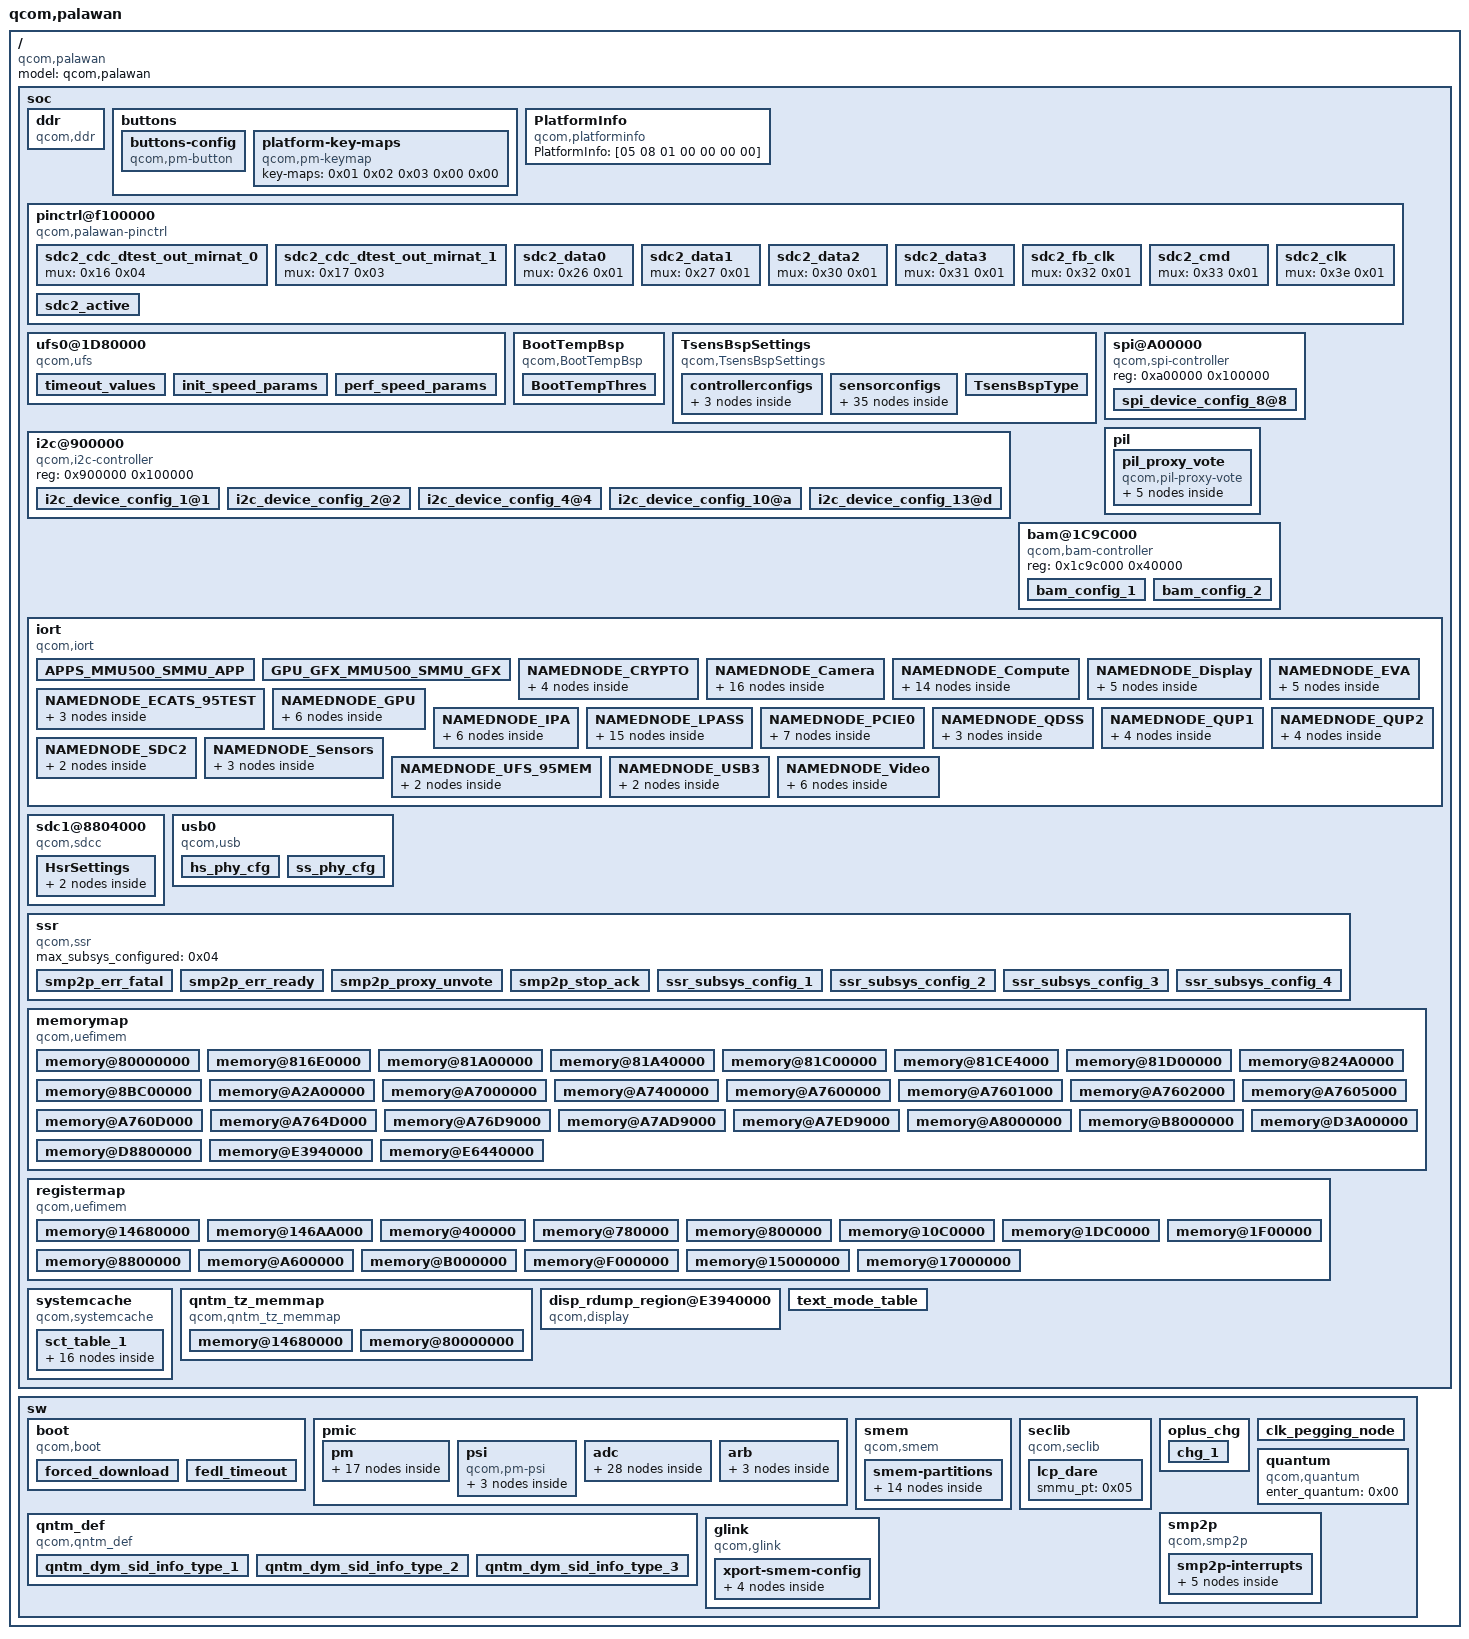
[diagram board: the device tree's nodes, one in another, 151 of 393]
/dts-v1/;

/ {
	compatible = "qcom,palawan";
	model = "qcom,palawan";
	#address-cells = <0x02>;
	#size-cells = <0x02>;

	soc {
		#address-cells = <0x01>;
		#size-cells = <0x01>;
		phandle = <0x10>;

		ddr {
			compatible = "qcom,ddr";
			print_severity = <0x2012>;
			ddr_log_level = <0x00>;
			ddr_trng_always_en = <0x00>;
			extnd_term_log_flag = <0x01>;
			ddr_tr_led_flag = <0x00>;
			ddr_boot_freq = <0x1fef00>;
		};

		buttons {
			phandle = <0x11>;

			buttons-config {
				compatible = "qcom,pm-button";
				gpio-configs = <0x00 0x01 0x01 0x05 0x00 0x01 0x00 0x00>;
			};

			platform-key-maps {
				compatible = "qcom,pm-keymap";
				key-maps = <0x01 0x02 0x03 0x00 0x00>;
			};
		};

		PlatformInfo {
			compatible = "qcom,platforminfo";
			PlatformInfo = [05 08 01 00 00 00 00];
		};

		pinctrl@f100000 {
			compatible = "qcom,palawan-pinctrl";
			reg = <0xf100000 0x100000>;
			ngpios = <0xb2>;
			width = <0x1000>;
			id = <0x00>;
			version = <0x01>;
			gpio-controller;
			#gpio-cells = <0x02>;
			qcom,sleep-config = <0x51 0x51 0x51 0x51 0x45 0x45 0x45 0x45 0x45 0x45 0x45 0x45 0x45 0x45 0x45 0x45 0x18a 0x18a 0x45 0x45 0x45 0x45 0x18a 0x45 0x45 0x45 0x45 0x45 0x45 0x45 0x45 0x151 0x151 0x45 0x45 0x45 0x18a 0x18a 0x45 0x45 0x45 0x45 0x18a 0x45 0x18a 0x18a 0x45 0x45 0x45 0x45 0x45 0x45 0x18a 0x18a 0x45 0x45 0x151 0x18a 0x18a 0x18a 0x45 0x45 0x45 0x45 0x45 0x45 0x45 0x45 0x45 0x45 0x45 0x45 0x45 0x45 0x45 0x45 0x45 0x45 0x45 0x45 0x45 0x18a 0x18a 0x45 0x45 0x45 0x45 0x45 0x152 0x152 0x152 0x45 0x151 0x151 0x151 0x151 0x151 0x151 0x151 0x151 0x45 0x45 0x45 0x45 0x45 0x45 0x45 0x45 0x45 0x45 0x45 0x45 0x45 0x45 0x45 0x45 0x45 0x151 0x18a 0x45 0x45 0x45 0x45 0x45 0x45 0x45 0x45 0x45 0x45 0x45 0x189 0x45 0x151 0x151 0x45 0x151 0x151 0x45 0x45 0x45 0x45 0x45 0x45 0x45 0x45 0x45 0x45 0x45 0x45 0x45 0x45 0x45 0x45 0x45 0x45 0x45 0x45 0x45 0x61 0x61 0x51 0x51 0x61 0x61 0x61 0x61 0x51 0x51 0x45 0x45 0x45 0x45 0x89 0x45 0x45 0x45 0x45 0x45>;
			phandle = <0x12>;

			sdc2_cdc_dtest_out_mirnat_0 {
				mux = <0x16 0x04>;
				phandle = <0x13>;
			};

			sdc2_cdc_dtest_out_mirnat_1 {
				mux = <0x17 0x03>;
				phandle = <0x14>;
			};

			sdc2_data0 {
				mux = <0x26 0x01>;
				phandle = <0x01>;
			};

			sdc2_data1 {
				mux = <0x27 0x01>;
				phandle = <0x02>;
			};

			sdc2_data2 {
				mux = <0x30 0x01>;
				phandle = <0x03>;
			};

			sdc2_data3 {
				mux = <0x31 0x01>;
				phandle = <0x04>;
			};

			sdc2_fb_clk {
				mux = <0x32 0x01>;
				phandle = <0x05>;
			};

			sdc2_cmd {
				mux = <0x33 0x01>;
				phandle = <0x06>;
			};

			sdc2_clk {
				mux = <0x3e 0x01>;
				phandle = <0x07>;
			};

			sdc2_active {
				config = <0x01 0x4b0000a 0x02 0x4b0000a 0x03 0x4b0000a 0x04 0x4b0000a 0x05 0x4b00012 0x06 0x4b00012 0x07 0x4b00012>;
				phandle = <0x0a>;
			};
		};

		ufs0@1D80000 {
			compatible = "qcom,ufs";
			reg = <0x1d80000 0x7000>;
			EnableLogging = [00];
			FUA_Value = [01];
			LinkStartupRetryCount = [05];
			BatteryThresholdMv = <0xe10>;
			phandle = <0x15>;

			timeout_values {
				fDeviceInitTimeoutUs = <0x2625a0>;
				UTRDPollTimeoutUs = <0x1c9c380>;
			};

			init_speed_params {
				EnableHighSpeed = [01];
				NumGears = [05];
				NumLanes = [02];
				Rate = [02];
			};

			perf_speed_params {
				EnableHighSpeed = [01];
				NumGears = [05];
				NumLanes = [02];
				Rate = [02];
			};
		};

		BootTempBsp {
			compatible = "qcom,BootTempBsp";

			BootTempThres {
				nUpperThresholdDegC = <0x96>;
				nLowerThresholdDegC = <0xffffff6a>;
				uMaxNumIterations = <0x28>;
				uWaitPerIterationMicroSec = <0x7a120>;
				uSensor = <0x00>;
			};
		};

		TsensBspSettings {
			compatible = "qcom,TsensBspSettings";

			controllerconfigs {

				controllerconfigs_0 {
					pucTsensSROTPhys = <0x00 0xc222000>;
					pucTsensTMPhys = <0x00 0xc228000>;
					pauTbcbReqs = <0x00 0x00>;
					uTsensSROTSize = <0x1000>;
					uTsensTMSize = <0x1000>;
					uNumTbcbClients = <0x00>;
					uPeriodActive = <0x00>;
					uPeriodSleep = <0x40>;
					uTSControl = <0x20000000>;
					uTSConfig = <0x00>;
					uSidebandEnMask = <0x3fff>;
					uWatchdogLoadVal = <0x267a>;
					uZeroCEnMask = <0x3fff>;
					nsZeroCSetDeciDegC = [00 32];
					nsZeroCResetDeciDegC = [00 64];
					bPSHoldResetEn = [01];
					bAutoAdjustPeriod = [01];
					bStandAlone = [00];
					bPWMEn = [00];
					bWatchdogEn = [01];
					bWatchdogResetEn = [01];
				};

				controllerconfigs_1 {
					pucTsensSROTPhys = <0x00 0xc223000>;
					pucTsensTMPhys = <0x00 0xc229000>;
					pauTbcbReqs = <0x00 0x00>;
					uTsensSROTSize = <0x1000>;
					uTsensTMSize = <0x1000>;
					uNumTbcbClients = <0x00>;
					uPeriodActive = <0x00>;
					uPeriodSleep = <0x40>;
					uTSControl = <0x20000000>;
					uTSConfig = <0x00>;
					uSidebandEnMask = <0xffff>;
					uWatchdogLoadVal = <0x267a>;
					uZeroCEnMask = <0xffff>;
					nsZeroCSetDeciDegC = [00 32];
					nsZeroCResetDeciDegC = [00 64];
					bPSHoldResetEn = [01];
					bAutoAdjustPeriod = [01];
					bStandAlone = [00];
					bPWMEn = [00];
					bWatchdogEn = [01];
					bWatchdogResetEn = [01];
				};

				controllerconfigs_2 {
					pucTsensSROTPhys = <0x00 0xc224000>;
					pucTsensTMPhys = <0x00 0xc22a000>;
					pauTbcbReqs = <0x00 0x00>;
					uTsensSROTSize = <0x1000>;
					uTsensTMSize = <0x1000>;
					uNumTbcbClients = <0x00>;
					uPeriodActive = <0x00>;
					uPeriodSleep = <0x40>;
					uTSControl = <0x20000000>;
					uTSConfig = <0x00>;
					uSidebandEnMask = <0x1f>;
					uWatchdogLoadVal = <0x267a>;
					uZeroCEnMask = <0x1f>;
					nsZeroCSetDeciDegC = [00 32];
					nsZeroCResetDeciDegC = [00 64];
					bPSHoldResetEn = [01];
					bAutoAdjustPeriod = [01];
					bStandAlone = [00];
					bPWMEn = [00];
					bWatchdogEn = [01];
					bWatchdogResetEn = [01];
				};
			};

			sensorconfigs {

				sensorconfigs_0 {
					eCal = <0x00>;
					nsCalPoint1CodeDefault = [01 e0];
					nsCalPoint2CodeDefault = [02 ca];
					nsThresholdMinDeciDegC = [7f ff];
					nsThresholdLowerDeciDegC = [7f ff];
					nsThresholdUpperDeciDegC = [7f ff];
					nsThresholdCriticalDeciDegC = [7f ff];
					nsThresholdMaxDeciDegC = [04 b0];
					controller = [00];
					ucChannel = [00];
					ucSensorID = [00];
					ucFuseIdx = [00];
				};

				sensorconfigs_1 {
					eCal = <0x00>;
					nsCalPoint1CodeDefault = [01 e0];
					nsCalPoint2CodeDefault = [02 ca];
					nsThresholdMinDeciDegC = [7f ff];
					nsThresholdLowerDeciDegC = [7f ff];
					nsThresholdUpperDeciDegC = [7f ff];
					nsThresholdCriticalDeciDegC = [7f ff];
					nsThresholdMaxDeciDegC = [04 b0];
					controller = [00];
					ucChannel = [01];
					ucSensorID = [01];
					ucFuseIdx = [01];
				};

				sensorconfigs_2 {
					eCal = <0x00>;
					nsCalPoint1CodeDefault = [01 e0];
					nsCalPoint2CodeDefault = [02 ca];
					nsThresholdMinDeciDegC = [7f ff];
					nsThresholdLowerDeciDegC = [7f ff];
					nsThresholdUpperDeciDegC = [7f ff];
					nsThresholdCriticalDeciDegC = [7f ff];
					nsThresholdMaxDeciDegC = [04 b0];
					controller = [00];
					ucChannel = [02];
					ucSensorID = [02];
					ucFuseIdx = [02];
				};

				sensorconfigs_3 {
					eCal = <0x00>;
					nsCalPoint1CodeDefault = [01 e0];
					nsCalPoint2CodeDefault = [02 ca];
					nsThresholdMinDeciDegC = [7f ff];
					nsThresholdLowerDeciDegC = [7f ff];
					nsThresholdUpperDeciDegC = [7f ff];
					nsThresholdCriticalDeciDegC = [7f ff];
					nsThresholdMaxDeciDegC = [04 b0];
					controller = [00];
					ucChannel = [03];
					ucSensorID = [03];
					ucFuseIdx = [03];
				};

				sensorconfigs_4 {
					eCal = <0x00>;
					nsCalPoint1CodeDefault = [01 e0];
					nsCalPoint2CodeDefault = [02 ca];
					nsThresholdMinDeciDegC = [7f ff];
					nsThresholdLowerDeciDegC = [7f ff];
					nsThresholdUpperDeciDegC = [7f ff];
					nsThresholdCriticalDeciDegC = [7f ff];
					nsThresholdMaxDeciDegC = [04 b0];
					controller = [00];
					ucChannel = [04];
					ucSensorID = [04];
					ucFuseIdx = [04];
				};

				sensorconfigs_5 {
					eCal = <0x00>;
					nsCalPoint1CodeDefault = [01 e0];
					nsCalPoint2CodeDefault = [02 ca];
					nsThresholdMinDeciDegC = [7f ff];
					nsThresholdLowerDeciDegC = [7f ff];
					nsThresholdUpperDeciDegC = [7f ff];
					nsThresholdCriticalDeciDegC = [7f ff];
					nsThresholdMaxDeciDegC = [04 b0];
					controller = [00];
					ucChannel = [05];
					ucSensorID = [05];
					ucFuseIdx = [05];
				};

				sensorconfigs_6 {
					eCal = <0x00>;
					nsCalPoint1CodeDefault = [01 e0];
					nsCalPoint2CodeDefault = [02 ca];
					nsThresholdMinDeciDegC = [7f ff];
					nsThresholdLowerDeciDegC = [7f ff];
					nsThresholdUpperDeciDegC = [7f ff];
					nsThresholdCriticalDeciDegC = [7f ff];
					nsThresholdMaxDeciDegC = [04 b0];
					controller = [00];
					ucChannel = [06];
					ucSensorID = [06];
					ucFuseIdx = [06];
				};

				sensorconfigs_7 {
					eCal = <0x00>;
					nsCalPoint1CodeDefault = [01 e0];
					nsCalPoint2CodeDefault = [02 ca];
					nsThresholdMinDeciDegC = [7f ff];
					nsThresholdLowerDeciDegC = [7f ff];
					nsThresholdUpperDeciDegC = [7f ff];
					nsThresholdCriticalDeciDegC = [7f ff];
					nsThresholdMaxDeciDegC = [04 b0];
					controller = [00];
					ucChannel = [07];
					ucSensorID = [07];
					ucFuseIdx = [07];
				};

				sensorconfigs_8 {
					eCal = <0x00>;
					nsCalPoint1CodeDefault = [01 e0];
					nsCalPoint2CodeDefault = [02 ca];
					nsThresholdMinDeciDegC = [7f ff];
					nsThresholdLowerDeciDegC = [7f ff];
					nsThresholdUpperDeciDegC = [7f ff];
					nsThresholdCriticalDeciDegC = [7f ff];
					nsThresholdMaxDeciDegC = [04 b0];
					controller = [00];
					ucChannel = [08];
					ucSensorID = [08];
					ucFuseIdx = [08];
				};

				sensorconfigs_9 {
					eCal = <0x00>;
					nsCalPoint1CodeDefault = [01 e0];
					nsCalPoint2CodeDefault = [02 ca];
					nsThresholdMinDeciDegC = [7f ff];
					nsThresholdLowerDeciDegC = [7f ff];
					nsThresholdUpperDeciDegC = [7f ff];
					nsThresholdCriticalDeciDegC = [7f ff];
					nsThresholdMaxDeciDegC = [04 b0];
					controller = [00];
					ucChannel = [09];
					ucSensorID = [09];
					ucFuseIdx = [09];
				};

				sensorconfigs_10 {
					eCal = <0x00>;
					nsCalPoint1CodeDefault = [01 e0];
					nsCalPoint2CodeDefault = [02 ca];
					nsThresholdMinDeciDegC = [7f ff];
					nsThresholdLowerDeciDegC = [7f ff];
					nsThresholdUpperDeciDegC = [7f ff];
					nsThresholdCriticalDeciDegC = [7f ff];
					nsThresholdMaxDeciDegC = [04 b0];
					controller = [00];
					ucChannel = [0a];
					ucSensorID = [0a];
					ucFuseIdx = [0a];
				};

				sensorconfigs_11 {
					eCal = <0x00>;
					nsCalPoint1CodeDefault = [01 e0];
					nsCalPoint2CodeDefault = [02 ca];
					nsThresholdMinDeciDegC = [7f ff];
					nsThresholdLowerDeciDegC = [7f ff];
					nsThresholdUpperDeciDegC = [7f ff];
					nsThresholdCriticalDeciDegC = [7f ff];
					nsThresholdMaxDeciDegC = [04 b0];
					controller = [00];
					ucChannel = [0b];
					ucSensorID = [0b];
					ucFuseIdx = [0b];
				};

				sensorconfigs_12 {
					eCal = <0x00>;
					nsCalPoint1CodeDefault = [01 e0];
					nsCalPoint2CodeDefault = [02 ca];
					nsThresholdMinDeciDegC = [7f ff];
					nsThresholdLowerDeciDegC = [7f ff];
					nsThresholdUpperDeciDegC = [7f ff];
					nsThresholdCriticalDeciDegC = [7f ff];
					nsThresholdMaxDeciDegC = [04 b0];
					controller = [00];
					ucChannel = [0c];
					ucSensorID = [0c];
					ucFuseIdx = [0c];
				};

				sensorconfigs_13 {
					eCal = <0x00>;
					nsCalPoint1CodeDefault = [01 e0];
					nsCalPoint2CodeDefault = [02 ca];
					nsThresholdMinDeciDegC = [7f ff];
					nsThresholdLowerDeciDegC = [7f ff];
					nsThresholdUpperDeciDegC = [7f ff];
					nsThresholdCriticalDeciDegC = [7f ff];
					nsThresholdMaxDeciDegC = [04 b0];
					controller = [00];
					ucChannel = [0d];
					ucSensorID = [0d];
					ucFuseIdx = [0d];
				};

				sensorconfigs_14 {
					eCal = <0x00>;
					nsCalPoint1CodeDefault = [01 e0];
					nsCalPoint2CodeDefault = [02 ca];
					nsThresholdMinDeciDegC = [7f ff];
					nsThresholdLowerDeciDegC = [7f ff];
					nsThresholdUpperDeciDegC = [7f ff];
					nsThresholdCriticalDeciDegC = [7f ff];
					nsThresholdMaxDeciDegC = [04 b0];
					controller = [01];
					ucChannel = [00];
					ucSensorID = [00];
					ucFuseIdx = [0e];
				};

				sensorconfigs_15 {
					eCal = <0x00>;
					nsCalPoint1CodeDefault = [01 e0];
					nsCalPoint2CodeDefault = [02 ca];
					nsThresholdMinDeciDegC = [7f ff];
					nsThresholdLowerDeciDegC = [7f ff];
					nsThresholdUpperDeciDegC = [7f ff];
					nsThresholdCriticalDeciDegC = [7f ff];
					nsThresholdMaxDeciDegC = [04 b0];
					controller = [01];
					ucChannel = [01];
					ucSensorID = [01];
					ucFuseIdx = [0f];
				};

				sensorconfigs_16 {
					eCal = <0x00>;
					nsCalPoint1CodeDefault = [01 e0];
					nsCalPoint2CodeDefault = [02 ca];
					nsThresholdMinDeciDegC = [7f ff];
					nsThresholdLowerDeciDegC = [7f ff];
					nsThresholdUpperDeciDegC = [7f ff];
					nsThresholdCriticalDeciDegC = [7f ff];
					nsThresholdMaxDeciDegC = [04 b0];
					controller = [01];
					ucChannel = [02];
					ucSensorID = [02];
					ucFuseIdx = [10];
				};

				sensorconfigs_17 {
					eCal = <0x00>;
					nsCalPoint1CodeDefault = [01 e0];
					nsCalPoint2CodeDefault = [02 ca];
					nsThresholdMinDeciDegC = [7f ff];
					nsThresholdLowerDeciDegC = [7f ff];
					nsThresholdUpperDeciDegC = [7f ff];
					nsThresholdCriticalDeciDegC = [7f ff];
					nsThresholdMaxDeciDegC = [04 b0];
					controller = [01];
					ucChannel = [03];
					ucSensorID = [03];
					ucFuseIdx = [11];
				};

				sensorconfigs_18 {
					eCal = <0x00>;
					nsCalPoint1CodeDefault = [01 e0];
					nsCalPoint2CodeDefault = [02 ca];
					nsThresholdMinDeciDegC = [7f ff];
					nsThresholdLowerDeciDegC = [7f ff];
					nsThresholdUpperDeciDegC = [7f ff];
					nsThresholdCriticalDeciDegC = [7f ff];
					nsThresholdMaxDeciDegC = [04 b0];
					controller = [01];
					ucChannel = [04];
					ucSensorID = [04];
					ucFuseIdx = [12];
				};

				sensorconfigs_19 {
					eCal = <0x00>;
					nsCalPoint1CodeDefault = [01 e0];
					nsCalPoint2CodeDefault = [02 ca];
					nsThresholdMinDeciDegC = [7f ff];
					nsThresholdLowerDeciDegC = [7f ff];
					nsThresholdUpperDeciDegC = [7f ff];
					nsThresholdCriticalDeciDegC = [7f ff];
					nsThresholdMaxDeciDegC = [04 b0];
					controller = [01];
					ucChannel = [05];
					ucSensorID = [05];
					ucFuseIdx = [13];
				};

				sensorconfigs_20 {
					eCal = <0x00>;
					nsCalPoint1CodeDefault = [01 e0];
					nsCalPoint2CodeDefault = [02 ca];
					nsThresholdMinDeciDegC = [7f ff];
					nsThresholdLowerDeciDegC = [7f ff];
					nsThresholdUpperDeciDegC = [7f ff];
					nsThresholdCriticalDeciDegC = [7f ff];
					nsThresholdMaxDeciDegC = [04 b0];
					controller = [01];
					ucChannel = [06];
					ucSensorID = [06];
					ucFuseIdx = [14];
				};

				sensorconfigs_21 {
					eCal = <0x00>;
					nsCalPoint1CodeDefault = [01 e0];
					nsCalPoint2CodeDefault = [02 ca];
					nsThresholdMinDeciDegC = [7f ff];
					nsThresholdLowerDeciDegC = [7f ff];
					nsThresholdUpperDeciDegC = [7f ff];
					nsThresholdCriticalDeciDegC = [7f ff];
					nsThresholdMaxDeciDegC = [04 b0];
					controller = [01];
					ucChannel = [07];
					ucSensorID = [07];
					ucFuseIdx = [15];
				};

				sensorconfigs_22 {
					eCal = <0x00>;
					nsCalPoint1CodeDefault = [01 e0];
					nsCalPoint2CodeDefault = [02 ca];
					nsThresholdMinDeciDegC = [7f ff];
					nsThresholdLowerDeciDegC = [7f ff];
					nsThresholdUpperDeciDegC = [7f ff];
					nsThresholdCriticalDeciDegC = [7f ff];
					nsThresholdMaxDeciDegC = [04 b0];
					controller = [01];
					ucChannel = [08];
					ucSensorID = [08];
					ucFuseIdx = [16];
				};

				sensorconfigs_23 {
					eCal = <0x00>;
					nsCalPoint1CodeDefault = [01 e0];
					nsCalPoint2CodeDefault = [02 ca];
					nsThresholdMinDeciDegC = [7f ff];
					nsThresholdLowerDeciDegC = [7f ff];
					nsThresholdUpperDeciDegC = [7f ff];
					nsThresholdCriticalDeciDegC = [7f ff];
					nsThresholdMaxDeciDegC = [04 b0];
					controller = [01];
					ucChannel = [09];
					ucSensorID = [09];
					ucFuseIdx = [17];
				};

				sensorconfigs_24 {
					eCal = <0x00>;
					nsCalPoint1CodeDefault = [01 e0];
					nsCalPoint2CodeDefault = [02 ca];
					nsThresholdMinDeciDegC = [7f ff];
					nsThresholdLowerDeciDegC = [7f ff];
					nsThresholdUpperDeciDegC = [7f ff];
					nsThresholdCriticalDeciDegC = [7f ff];
					nsThresholdMaxDeciDegC = [04 b0];
					controller = [01];
					ucChannel = [0a];
					ucSensorID = [0a];
					ucFuseIdx = [18];
				};

				sensorconfigs_25 {
					eCal = <0x00>;
					nsCalPoint1CodeDefault = [01 e0];
					nsCalPoint2CodeDefault = [02 ca];
					nsThresholdMinDeciDegC = [7f ff];
					nsThresholdLowerDeciDegC = [7f ff];
					nsThresholdUpperDeciDegC = [7f ff];
					nsThresholdCriticalDeciDegC = [7f ff];
					nsThresholdMaxDeciDegC = [04 b0];
					controller = [01];
					ucChannel = [0b];
					ucSensorID = [0b];
					ucFuseIdx = [19];
				};

				sensorconfigs_26 {
					eCal = <0x00>;
					nsCalPoint1CodeDefault = [01 e0];
					nsCalPoint2CodeDefault = [02 ca];
					nsThresholdMinDeciDegC = [7f ff];
					nsThresholdLowerDeciDegC = [7f ff];
					nsThresholdUpperDeciDegC = [7f ff];
					nsThresholdCriticalDeciDegC = [7f ff];
					nsThresholdMaxDeciDegC = [04 b0];
					controller = [01];
					ucChannel = [0c];
					ucSensorID = [0c];
					ucFuseIdx = [1a];
				};

				sensorconfigs_27 {
					eCal = <0x00>;
					nsCalPoint1CodeDefault = [01 e0];
					nsCalPoint2CodeDefault = [02 ca];
					nsThresholdMinDeciDegC = [7f ff];
					nsThresholdLowerDeciDegC = [7f ff];
					nsThresholdUpperDeciDegC = [7f ff];
					nsThresholdCriticalDeciDegC = [7f ff];
					nsThresholdMaxDeciDegC = [04 b0];
					controller = [01];
					ucChannel = [0d];
					ucSensorID = [0d];
					ucFuseIdx = [1b];
				};

				sensorconfigs_28 {
					eCal = <0x00>;
					nsCalPoint1CodeDefault = [01 e0];
					nsCalPoint2CodeDefault = [02 ca];
					nsThresholdMinDeciDegC = [7f ff];
					nsThresholdLowerDeciDegC = [7f ff];
					nsThresholdUpperDeciDegC = [7f ff];
					nsThresholdCriticalDeciDegC = [7f ff];
					nsThresholdMaxDeciDegC = [04 b0];
					controller = [01];
					ucChannel = [0e];
					ucSensorID = [0e];
					ucFuseIdx = [1c];
				};

				sensorconfigs_29 {
					eCal = <0x00>;
					nsCalPoint1CodeDefault = [01 e0];
					nsCalPoint2CodeDefault = [02 ca];
					nsThresholdMinDeciDegC = [7f ff];
					nsThresholdLowerDeciDegC = [7f ff];
					nsThresholdUpperDeciDegC = [7f ff];
					nsThresholdCriticalDeciDegC = [7f ff];
					nsThresholdMaxDeciDegC = [04 b0];
					controller = [01];
					ucChannel = [0f];
					ucSensorID = [0f];
					ucFuseIdx = [1d];
				};

				sensorconfigs_30 {
					eCal = <0x00>;
					nsCalPoint1CodeDefault = [01 e0];
					nsCalPoint2CodeDefault = [02 ca];
					nsThresholdMinDeciDegC = [7f ff];
					nsThresholdLowerDeciDegC = [7f ff];
					nsThresholdUpperDeciDegC = [7f ff];
					nsThresholdCriticalDeciDegC = [7f ff];
					nsThresholdMaxDeciDegC = [04 b0];
					controller = [02];
					ucChannel = [00];
					ucSensorID = [00];
					ucFuseIdx = [1e];
				};

				sensorconfigs_31 {
					eCal = <0x00>;
					nsCalPoint1CodeDefault = [01 e0];
					nsCalPoint2CodeDefault = [02 ca];
					nsThresholdMinDeciDegC = [7f ff];
					nsThresholdLowerDeciDegC = [7f ff];
					nsThresholdUpperDeciDegC = [7f ff];
					nsThresholdCriticalDeciDegC = [7f ff];
					nsThresholdMaxDeciDegC = [04 b0];
					controller = [02];
					ucChannel = [01];
					ucSensorID = [01];
					ucFuseIdx = [1f];
				};

				sensorconfigs_32 {
					eCal = <0x00>;
					nsCalPoint1CodeDefault = [01 e0];
					nsCalPoint2CodeDefault = [02 ca];
					nsThresholdMinDeciDegC = [7f ff];
					nsThresholdLowerDeciDegC = [7f ff];
					nsThresholdUpperDeciDegC = [7f ff];
					nsThresholdCriticalDeciDegC = [7f ff];
					nsThresholdMaxDeciDegC = [04 b0];
					controller = [02];
					ucChannel = [02];
					ucSensorID = [02];
					ucFuseIdx = [20];
				};

				sensorconfigs_33 {
					eCal = <0x00>;
					nsCalPoint1CodeDefault = [01 e0];
					nsCalPoint2CodeDefault = [02 ca];
					nsThresholdMinDeciDegC = [7f ff];
					nsThresholdLowerDeciDegC = [7f ff];
					nsThresholdUpperDeciDegC = [7f ff];
					nsThresholdCriticalDeciDegC = [7f ff];
					nsThresholdMaxDeciDegC = [04 b0];
					controller = [02];
					ucChannel = [03];
					ucSensorID = [03];
					ucFuseIdx = [21];
				};

				sensorconfigs_34 {
					eCal = <0x00>;
					nsCalPoint1CodeDefault = [01 e0];
					nsCalPoint2CodeDefault = [02 ca];
					nsThresholdMinDeciDegC = [7f ff];
					nsThresholdLowerDeciDegC = [7f ff];
					nsThresholdUpperDeciDegC = [7f ff];
					nsThresholdCriticalDeciDegC = [7f ff];
					nsThresholdMaxDeciDegC = [04 b0];
					controller = [02];
					ucChannel = [04];
					ucSensorID = [04];
					ucFuseIdx = [22];
				};
			};

			TsensBspType {
				uNumControllers = <0x03>;
				uNumSensors = <0x23>;
				uSensorConvTime_us = <0x1e>;
				nCalPoint1DeciDegC = <0x12c>;
				nCalPoint2DeciDegC = <0x4b0>;
				uShift = <0x0a>;
			};
		};

		i2c@900000 {
			#address-cells = <0x01>;
			#size-cells = <0x00>;
			compatible = "qcom,i2c-controller";
			reg = <0x900000 0x100000>;

			i2c_device_config_1@1 {
				reg = <0x01>;
				status = "okay";
				core_base_addr = <0xa00000>;
				common_base_addr = <0xac0000>;
				core_offset = <0x80000>;
				qupv3_instance = [00];
				core_index = [01];
				se_index = [00];
				gpi_index = [00];
				core_irq = [00];
				polled_mode = [01];
				i2c_hub = [00];
				min_data_length_for_dma = [00];
				scl_encoding = <0x40018351>;
				sda_encoding = <0x40018341>;
				tcsr_reg_offset = <0x00>;
				tcsr_base_addr = <0x1fc0000>;
				tcsr_reg_value = <0x00>;
				se_clock = "gcc_qupv3_wrap0_s0_clk";
			};

			i2c_device_config_2@2 {
				reg = <0x02>;
				status = "okay";
				core_base_addr = <0xa00000>;
				common_base_addr = <0xac0000>;
				core_offset = "", "\b@";
				qupv3_instance = [00];
				core_index = [02];
				se_index = [01];
				gpi_index = [00];
				core_irq = [00];
				polled_mode = [01];
				i2c_hub = [00];
				min_data_length_for_dma = [00];
				scl_encoding = <0x18051>;
				sda_encoding = <0x18041>;
				tcsr_reg_offset = <0x00>;
				tcsr_base_addr = <0x1fc0000>;
				tcsr_reg_value = <0x00>;
				se_clock = "gcc_qupv3_wrap0_s1_clk";
			};

			i2c_device_config_4@4 {
				reg = <0x04>;
				status = "okay";
				core_base_addr = <0xa00000>;
				common_base_addr = <0xac0000>;
				core_offset = <0x8c000>;
				qupv3_instance = [00];
				core_index = [04];
				se_index = [03];
				gpi_index = [03];
				core_irq = [00];
				polled_mode = [01];
				i2c_hub = [00];
				min_data_length_for_dma = [00];
				scl_encoding = <0x400180d2>;
				sda_encoding = <0x400180c2>;
				tcsr_reg_offset = <0x00>;
				tcsr_base_addr = <0x1fc0000>;
				tcsr_reg_value = <0x00>;
				se_clock = "gcc_qupv3_wrap0_s3_clk";
			};

			i2c_device_config_10@a {
				reg = <0x0a>;
				status = "okay";
				core_base_addr = <0x800000>;
				common_base_addr = <0x8c0000>;
				core_offset = "", "\b@";
				qupv3_instance = [01];
				core_index = [0a];
				se_index = [01];
				gpi_index = [09];
				core_irq = [00];
				polled_mode = [01];
				i2c_hub = [00];
				min_data_length_for_dma = [00];
				scl_encoding = <0x18251>;
				sda_encoding = <0x18241>;
				tcsr_reg_offset = <0x00>;
				tcsr_base_addr = <0x1fc0000>;
				tcsr_reg_value = <0x00>;
				se_clock = "gcc_qupv3_wrap1_s1_clk";
			};

			i2c_device_config_13@d {
				reg = <0x0d>;
				status = "okay";
				core_base_addr = <0x800000>;
				common_base_addr = <0x8c0000>;
				core_offset = <0x90000>;
				qupv3_instance = [01];
				core_index = [0d];
				se_index = [04];
				gpi_index = [0c];
				core_irq = [00];
				polled_mode = [01];
				i2c_hub = [00];
				min_data_length_for_dma = [00];
				scl_encoding = <0x18b11>;
				sda_encoding = <0x18b01>;
				tcsr_reg_offset = <0x00>;
				tcsr_base_addr = <0x1fc0000>;
				tcsr_reg_value = <0x00>;
				se_clock = "gcc_qupv3_wrap1_s4_clk";
			};
		};

		spi@A00000 {
			#address-cells = <0x01>;
			#size-cells = <0x00>;
			compatible = "qcom,spi-controller";
			reg = <0xa00000 0x100000>;

			spi_device_config_8@8 {
				reg = <0x08>;
				status = "okay";
				core_base_addr = <0xa00000>;
				common_base_addr = <0xac0000>;
				core_offset = <0x9c000>;
				qupv3_instance = [00];
				core_index = [07];
				se_index = [07];
				gpi_index = [07];
				core_irq = [00];
				polled_mode = [01];
				min_data_length_for_dma = [00];
				qupv3_protocol = [01];
				miso_encoding = <0x481c1>;
				mosi_encoding = <0x4c1d1>;
				clk_encoding = <0x441e1>;
				cs_encoding = <0x4c1f1>;
				sleep_miso_encoding = <0x00>;
				sleep_mosi_encoding = <0x00>;
				sleep_clk_encoding = <0x00>;
				sleep_cs_encoding = <0x00>;
				tcsr_reg_offset = <0x00>;
				tcsr_base_addr = <0x1fc0000>;
				tcsr_reg_value = <0x00>;
				se_clock_frequency = <0x4b00>;
				se_clock_dfs_index = [01];
				se_clock = "gcc_qupv3_wrap0_s7_clk";
			};
		};

		pil {

			pil_proxy_vote {
				compatible = "qcom,pil-proxy-vote";
				phandle = <0x16>;

				pil_proxy_vote_1 {
					subsys_id = <0x01>;
					client_name = "PIL_ADSP";
					rail_names = "/vcs/vdd_lpi_mx", "/vcs/vdd_lpi_cx";
					rail_voltage_levels = <0x100 0x100>;
					icb_name = "/icb/arbiter";
					icb_arb_master_slave = <0x19 0x00>;
					icb_arb_request_type = <0x04>;
					icb_arb_request_data = <0x00 0x5f5e100 0x00 0x5f5e100>;
					flag = <0x03 0x03>;
				};

				pil_proxy_vote_4 {
					subsys_id = <0x04>;
					client_name = "PIL_MODEM";
					rail_names = "/vcs/vdd_mx", "/vcs/vdd_cx", "/vcs/vdd_mxc";
					rail_voltage_levels = <0x100 0x100 0x100>;
					flag = <0x03 0x03>;
				};

				pil_proxy_vote_18 {
					subsys_id = <0x12>;
					client_name = "PIL_CDSP";
					rail_names = "/vcs/vdd_mx", "/vcs/vdd_cx", "/vcs/vdd_mxc", "/vcs/vdd_nsp";
					rail_voltage_levels = <0x100 0x100 0x100 0x100>;
					icb_name = "/icb/arbiter";
					icb_arb_master_slave = <0xad 0x2f>;
					icb_arb_request_type = <0x04>;
					icb_arb_request_data = <0x00 0x5f5e100 0x00 0x5f5e100>;
					flag = <0x02 0x01>;
				};

				pil_proxy_vote_37 {
					subsys_id = <0x25>;
					client_name = "PIL_CDSP";
					rail_names = "/vcs/vdd_mx", "/vcs/vdd_cx", "/vcs/vdd_mxc", "/vcs/vdd_nsp";
					rail_voltage_levels = <0x100 0x100 0x100 0x100>;
					icb_name = "/icb/arbiter";
					icb_arb_master_slave = <0xad 0x2f>;
					icb_arb_request_type = <0x04>;
					icb_arb_request_data = <0x00 0x5f5e100 0x00 0x5f5e100>;
					flag = <0x11 0x12>;
				};

				pil_proxy_vote_6 {
					subsys_id = <0x06>;
					client_name = "PIL_WPSS";
					rail_names = "/vcs/vdd_mx", "/vcs/vdd_cx";
					rail_voltage_levels = <0x100 0x100>;
					flag = <0x03 0x03>;
				};
			};
		};

		bam@1C9C000 {
			compatible = "qcom,bam-controller";
			reg = <0x1c9c000 0x40000>;

			bam_config_1 {
				bam_pa = <0x00 0x1dc4000>;
				options = <0x100>;
				cfg_bits = <0xfffff004>;
				ee = [00];
				sec_config = <0x00 0x00>;
				size = <0x40000>;
			};

			bam_config_2 {
				bam_pa = <0x00 0x00>;
				options = <0x00>;
				cfg_bits = <0x00>;
				ee = [00];
				sec_config = <0x00 0x00>;
				size = <0x00>;
			};
		};

		iort {
			compatible = "qcom,iort";
			Signature = <0x54524f49>;
			Revision = <0x01>;
			Checksum = <0x00>;
			OEMID = "QCOM";
			OEMTableID = <0x51434f4d 0x45444b32>;
			OEMRevision = <0x8998>;
			CreatorID = <0x51434f4d>;
			CreatorRevision = <0x01>;
			NumberofIORTNodes = <0x14>;
			Reserved = <0x00>;
			instance_handles = <0x08 0x09>;

			APPS_MMU500_SMMU_APP {
				Type = <0x03>;
				Revision = <0x01>;
				Reserved = <0x00>;
				NumberofMappings = <0x00>;
				BaseAddress = <0x15000000>;
				Span = <0x80000>;
				Flags = <0x03>;
				Model = <0x03>;
				NumContextInterrupts = <0x60>;
				NumPMUInterrupts = <0x00>;
				NSGIRPT_GSIV = <0x61>;
				NSGIRPT_FLAGS = <0x00>;
				NSGCFGIRPT_GSIV = <0x00>;
				NSGCFGIRPT_FLAGS = <0x00>;
				ContextInterrupts = <0x81 0x82 0x83 0x84 0x85 0x86 0x87 0x88 0x89 0x8a 0x8b 0x8c 0x8d 0x8e 0x8f 0x90 0x91 0x92 0x93 0x94 0x95 0x96 0xd5 0xd6 0xd7 0xd8 0xd9 0xda 0xdb 0xdc 0xdd 0xde 0xdf 0xe0 0x15b 0x15c 0x15d 0x15e 0x15f 0x160 0x161 0x162 0x163 0x164 0x165 0x166 0x167 0x168 0x169 0x16a 0x16b 0x16c 0x16d 0x16e 0x16f 0x170 0x171 0x172 0x173 0x174 0x175 0x176 0x177 0x178 0x179 0x1ab 0x1ac 0x1ad 0x1ae 0x1af 0x1b0 0x1b1 0x1b2 0x1b3 0x1b4 0x1b5 0x1b6 0x1b7 0x1b8 0x1b9 0x1c2 0x1c3 0x1bc 0x1c5 0x2e2 0x1c7 0x1c8 0x1c9 0x2d1 0x2d2 0x2d3 0x2d4 0x2d5 0x2d6 0x2d7 0x2d8>;
				ContextInterruptFlags = <0x00 0x00 0x00 0x00 0x00 0x00 0x00 0x00 0x00 0x00 0x00 0x00 0x00 0x00 0x00 0x00 0x00 0x00 0x00 0x00 0x00 0x00 0x00 0x00 0x00 0x00 0x00 0x00 0x00 0x00 0x00 0x00 0x00 0x00 0x00 0x00 0x00 0x00 0x00 0x00 0x00 0x00 0x00 0x00 0x00 0x00 0x00 0x00 0x00 0x00 0x00 0x00 0x00 0x00 0x00 0x00 0x00 0x00 0x00 0x00 0x00 0x00 0x00 0x00 0x00 0x00 0x00 0x00 0x00 0x00 0x00 0x00 0x00 0x00 0x00 0x00 0x00 0x00 0x00 0x00 0x00 0x00 0x00 0x00 0x00 0x00 0x00 0x00 0x00 0x00 0x00 0x00 0x00 0x00 0x00 0x00>;
				PMUInterrupts = <0x00>;
				PMUInterruptFlags = <0x00>;
				SIDMAPPING = <0x00>;
				phandle = <0x08>;
			};

			GPU_GFX_MMU500_SMMU_GFX {
				Type = <0x03>;
				Revision = <0x01>;
				Reserved = <0x00>;
				NumberofMappings = <0x00>;
				BaseAddress = <0x3da0000>;
				Span = <0x20000>;
				Flags = <0x03>;
				Model = <0x03>;
				NumContextInterrupts = <0x19>;
				NumPMUInterrupts = <0x00>;
				NSGIRPT_GSIV = <0x2c1>;
				NSGIRPT_FLAGS = <0x00>;
				NSGCFGIRPT_GSIV = <0x00>;
				NSGCFGIRPT_FLAGS = <0x00>;
				ContextInterrupts = <0x2c5 0x2c6 0x2c7 0x2c8 0x2c9 0x2ca 0x2cb 0x2cc 0x2cd 0x2ce 0x2cf 0x1c6 0x1fc 0x25e 0x25f 0x260 0x261 0x2b3 0x2b5 0x2b8 0x2b9 0x2ba 0x2bc 0x2bd 0x2db>;
				ContextInterruptFlags = <0x00 0x00 0x00 0x00 0x00 0x00 0x00 0x00 0x00 0x00 0x00 0x00 0x00 0x00 0x00 0x00 0x00 0x00 0x00 0x00 0x00 0x00 0x00 0x00 0x00>;
				PMUInterrupts = <0x00>;
				PMUInterruptFlags = <0x00>;
				SIDMAPPING = <0x00>;
				phandle = <0x09>;
			};

			NAMEDNODE_CRYPTO {
				Type = <0x01>;
				Revision = <0x01>;
				Reserved = <0x00>;
				NumberofMappings = <0x03>;
				NodeFlags = <0x00>;
				CacheCoherency = <0x00>;
				AllocationHints = <0x00>;
				Reserved1 = <0x00>;
				MemAccessFlags = <0x00>;
				DeviceMemAddressSize = <0x24>;
				DevObjectName = "CRYPTO";

				SIDMappings {

					SIDMappings_1 {
						InputBase = <0x3000001>;
						NumIDs = <0x01>;
						OutputBase = <0x481>;
						Flags = <0x00>;
						OutputReference = <0x08>;
					};

					SIDMappings_2 {
						InputBase = <0x3000002>;
						NumIDs = <0x01>;
						OutputBase = <0x480>;
						Flags = <0x00>;
						OutputReference = <0x08>;
					};

					SIDMappings_3 {
						InputBase = <0x3000003>;
						NumIDs = <0x01>;
						OutputBase = <0x483>;
						Flags = <0x00>;
						OutputReference = <0x08>;
					};
				};
			};

			NAMEDNODE_Camera {
				Type = <0x01>;
				Revision = <0x01>;
				Reserved = <0x00>;
				NumberofMappings = <0x0f>;
				NodeFlags = <0x00>;
				CacheCoherency = <0x00>;
				AllocationHints = <0x00>;
				Reserved1 = <0x00>;
				MemAccessFlags = <0x00>;
				DeviceMemAddressSize = <0x24>;
				DevObjectName = "CAMERA";

				SIDMappings {

					SIDMappings_0 {
						InputBase = <0x3000000>;
						NumIDs = <0x01>;
						OutputBase = "", " \b";
						Flags = <0x00>;
						OutputReference = <0x08>;
					};

					SIDMappings_1 {
						InputBase = <0x3000001>;
						NumIDs = <0x01>;
						OutputBase = <0x10200808>;
						Flags = <0x00>;
						OutputReference = <0x08>;
					};

					SIDMappings_3 {
						InputBase = <0x3000003>;
						NumIDs = <0x01>;
						OutputBase = <0x1820>;
						Flags = <0x00>;
						OutputReference = <0x08>;
					};

					SIDMappings_5 {
						InputBase = <0x3000005>;
						NumIDs = <0x01>;
						OutputBase = <0x18c0>;
						Flags = <0x00>;
						OutputReference = <0x08>;
					};

					SIDMappings_6 {
						InputBase = <0x3000006>;
						NumIDs = <0x01>;
						OutputBase = <0x18c2>;
						Flags = <0x00>;
						OutputReference = <0x08>;
					};

					SIDMappings_7 {
						InputBase = <0x3000007>;
						NumIDs = <0x01>;
						OutputBase = <0x1800>;
						Flags = <0x00>;
						OutputReference = <0x08>;
					};

					SIDMappings_8 {
						InputBase = <0x3000008>;
						NumIDs = <0x01>;
						OutputBase = <0x18a0>;
						Flags = <0x00>;
						OutputReference = <0x08>;
					};

					SIDMappings_9 {
						InputBase = <0x3000009>;
						NumIDs = <0x01>;
						OutputBase = <0x1860>;
						Flags = <0x00>;
						OutputReference = <0x08>;
					};

					SIDMappings_10 {
						InputBase = <0x300000a>;
						NumIDs = <0x01>;
						OutputBase = <0x1861>;
						Flags = <0x00>;
						OutputReference = <0x08>;
					};

					SIDMappings_11 {
						InputBase = <0x300000b>;
						NumIDs = <0x01>;
						OutputBase = <0x1840>;
						Flags = <0x00>;
						OutputReference = <0x08>;
					};

					SIDMappings_12 {
						InputBase = <0x300000c>;
						NumIDs = <0x01>;
						OutputBase = <0x1841>;
						Flags = <0x00>;
						OutputReference = <0x08>;
					};

					SIDMappings_13 {
						InputBase = <0x300000d>;
						NumIDs = <0x01>;
						OutputBase = <0x1880>;
						Flags = <0x00>;
						OutputReference = <0x08>;
					};

					SIDMappings_14 {
						InputBase = <0x300000e>;
						NumIDs = <0x01>;
						OutputBase = <0x1881>;
						Flags = <0x00>;
						OutputReference = <0x08>;
					};

					SIDMappings_15 {
						InputBase = <0x300000f>;
						NumIDs = <0x01>;
						OutputBase = <0x18e0>;
						Flags = <0x00>;
						OutputReference = <0x08>;
					};

					SIDMappings_16 {
						InputBase = <0x3000010>;
						NumIDs = <0x01>;
						OutputBase = <0x18e8>;
						Flags = <0x00>;
						OutputReference = <0x08>;
					};
				};
			};

			NAMEDNODE_Compute {
				Type = <0x01>;
				Revision = <0x01>;
				Reserved = <0x00>;
				NumberofMappings = <0x0d>;
				NodeFlags = <0x00>;
				CacheCoherency = <0x00>;
				AllocationHints = <0x00>;
				Reserved1 = <0x00>;
				MemAccessFlags = <0x00>;
				DeviceMemAddressSize = <0x24>;
				DevObjectName = "COMPUTE";

				SIDMappings {

					SIDMappings_1 {
						InputBase = <0x3000001>;
						NumIDs = <0x01>;
						OutputBase = <0xc01>;
						Flags = <0x00>;
						OutputReference = <0x08>;
					};

					SIDMappings_2 {
						InputBase = <0x3000002>;
						NumIDs = <0x01>;
						OutputBase = <0xc02>;
						Flags = <0x00>;
						OutputReference = <0x08>;
					};

					SIDMappings_3 {
						InputBase = <0x3000003>;
						NumIDs = <0x01>;
						OutputBase = <0xc03>;
						Flags = <0x00>;
						OutputReference = <0x08>;
					};

					SIDMappings_4 {
						InputBase = <0x3000004>;
						NumIDs = <0x01>;
						OutputBase = <0xc04>;
						Flags = <0x00>;
						OutputReference = <0x08>;
					};

					SIDMappings_5 {
						InputBase = <0x3000005>;
						NumIDs = <0x01>;
						OutputBase = <0xc05>;
						Flags = <0x00>;
						OutputReference = <0x08>;
					};

					SIDMappings_6 {
						InputBase = <0x3000006>;
						NumIDs = <0x01>;
						OutputBase = <0xc06>;
						Flags = <0x00>;
						OutputReference = <0x08>;
					};

					SIDMappings_7 {
						InputBase = <0x3000007>;
						NumIDs = <0x01>;
						OutputBase = <0xc07>;
						Flags = <0x00>;
						OutputReference = <0x08>;
					};

					SIDMappings_8 {
						InputBase = <0x3000008>;
						NumIDs = <0x01>;
						OutputBase = <0xc08>;
						Flags = <0x00>;
						OutputReference = <0x08>;
					};

					SIDMappings_9 {
						InputBase = <0x3000009>;
						NumIDs = <0x01>;
						OutputBase = <0xc09>;
						Flags = <0x00>;
						OutputReference = <0x08>;
					};

					SIDMappings_11 {
						InputBase = <0x300000b>;
						NumIDs = <0x01>;
						OutputBase = <0xc0b>;
						Flags = <0x00>;
						OutputReference = <0x08>;
					};

					SIDMappings_12 {
						InputBase = <0x300000c>;
						NumIDs = <0x01>;
						OutputBase = <0xc0c>;
						Flags = <0x00>;
						OutputReference = <0x08>;
					};

					SIDMappings_13 {
						InputBase = <0x300000d>;
						NumIDs = <0x01>;
						OutputBase = <0xc0d>;
						Flags = <0x00>;
						OutputReference = <0x08>;
					};

					SIDMappings_14 {
						InputBase = <0x300000e>;
						NumIDs = <0x01>;
						OutputBase = <0xc0e>;
						Flags = <0x00>;
						OutputReference = <0x08>;
					};
				};
			};

			NAMEDNODE_Display {
				Type = <0x01>;
				Revision = <0x01>;
				Reserved = <0x00>;
				NumberofMappings = <0x04>;
				NodeFlags = <0x00>;
				CacheCoherency = <0x00>;
				AllocationHints = <0x00>;
				Reserved1 = <0x00>;
				MemAccessFlags = <0x00>;
				DeviceMemAddressSize = <0x24>;
				DevObjectName = "DISPLAY";

				SIDMappings {

					SIDMappings_0 {
						InputBase = <0x3000000>;
						NumIDs = <0x01>;
						OutputBase = <0x21c00>;
						Flags = <0x00>;
						OutputReference = <0x08>;
					};

					SIDMappings_2 {
						InputBase = <0x3000002>;
						NumIDs = <0x01>;
						OutputBase = <0x1c01>;
						Flags = <0x00>;
						OutputReference = <0x08>;
					};

					SIDMappings_3 {
						InputBase = <0x3000003>;
						NumIDs = <0x01>;
						OutputBase = <0x1c04>;
						Flags = <0x00>;
						OutputReference = <0x08>;
					};

					SIDMappings_4 {
						InputBase = <0x3000004>;
						NumIDs = <0x01>;
						OutputBase = <0x1c06>;
						Flags = <0x00>;
						OutputReference = <0x08>;
					};
				};
			};

			NAMEDNODE_ECATS_95TEST {
				Type = <0x01>;
				Revision = <0x01>;
				Reserved = <0x00>;
				NumberofMappings = <0x02>;
				NodeFlags = <0x00>;
				CacheCoherency = <0x00>;
				AllocationHints = <0x00>;
				Reserved1 = <0x00>;
				MemAccessFlags = <0x00>;
				DeviceMemAddressSize = <0x24>;
				DevObjectName = "ECATS_TEST";

				SIDMappings {

					SIDMappings_0 {
						InputBase = <0x3000000>;
						NumIDs = <0x01>;
						OutputBase = <0x400>;
						Flags = <0x00>;
						OutputReference = <0x08>;
					};

					SIDMappings_1 {
						InputBase = <0x3000001>;
						NumIDs = <0x01>;
						OutputBase = <0x401>;
						Flags = <0x00>;
						OutputReference = <0x08>;
					};
				};
			};

			NAMEDNODE_EVA {
				Type = <0x01>;
				Revision = <0x01>;
				Reserved = <0x00>;
				NumberofMappings = <0x04>;
				NodeFlags = <0x00>;
				CacheCoherency = <0x00>;
				AllocationHints = <0x00>;
				Reserved1 = <0x00>;
				MemAccessFlags = <0x00>;
				DeviceMemAddressSize = <0x24>;
				DevObjectName = "EVA";

				SIDMappings {

					SIDMappings_0 {
						InputBase = <0x3000000>;
						NumIDs = <0x01>;
						OutputBase = <0x1920>;
						Flags = <0x00>;
						OutputReference = <0x08>;
					};

					SIDMappings_1 {
						InputBase = <0x43000001>;
						NumIDs = <0x01>;
						OutputBase = <0x1920>;
						Flags = <0x00>;
						OutputReference = <0x08>;
					};

					SIDMappings_3 {
						InputBase = <0x3000003>;
						NumIDs = <0x01>;
						OutputBase = <0x1923>;
						Flags = <0x00>;
						OutputReference = <0x08>;
					};

					SIDMappings_4 {
						InputBase = <0x3000004>;
						NumIDs = <0x01>;
						OutputBase = <0x1924>;
						Flags = <0x00>;
						OutputReference = <0x08>;
					};
				};
			};

			NAMEDNODE_GPU {
				Type = <0x01>;
				Revision = <0x01>;
				Reserved = <0x00>;
				NumberofMappings = <0x05>;
				NodeFlags = <0x00>;
				CacheCoherency = <0x00>;
				AllocationHints = <0x00>;
				Reserved1 = <0x00>;
				MemAccessFlags = <0x00>;
				DeviceMemAddressSize = <0x24>;
				DevObjectName = "GPU";

				SIDMappings {

					SIDMappings_0 {
						InputBase = <0x3000000>;
						NumIDs = <0x01>;
						OutputBase = <0x00>;
						Flags = <0x00>;
						OutputReference = <0x09>;
					};

					SIDMappings_1 {
						InputBase = <0x3000001>;
						NumIDs = <0x01>;
						OutputBase = <0x02>;
						Flags = <0x00>;
						OutputReference = <0x09>;
					};

					SIDMappings_3 {
						InputBase = <0x3000003>;
						NumIDs = <0x01>;
						OutputBase = <0x04>;
						Flags = <0x00>;
						OutputReference = <0x09>;
					};

					SIDMappings_4 {
						InputBase = <0x3000004>;
						NumIDs = <0x01>;
						OutputBase = <0x05>;
						Flags = <0x00>;
						OutputReference = <0x09>;
					};

					SIDMappings_5 {
						InputBase = <0x3000005>;
						NumIDs = <0x01>;
						OutputBase = <0x07>;
						Flags = <0x00>;
						OutputReference = <0x09>;
					};
				};
			};

			NAMEDNODE_IPA {
				Type = <0x01>;
				Revision = <0x01>;
				Reserved = <0x00>;
				NumberofMappings = <0x05>;
				NodeFlags = <0x00>;
				CacheCoherency = <0x00>;
				AllocationHints = <0x00>;
				Reserved1 = <0x00>;
				MemAccessFlags = <0x00>;
				DeviceMemAddressSize = <0x24>;
				DevObjectName = "IPA";

				SIDMappings {

					SIDMappings_0 {
						InputBase = <0x3000000>;
						NumIDs = <0x01>;
						OutputBase = <0x4a0>;
						Flags = <0x00>;
						OutputReference = <0x08>;
					};

					SIDMappings_1 {
						InputBase = <0x3000001>;
						NumIDs = <0x01>;
						OutputBase = <0x4a1>;
						Flags = <0x00>;
						OutputReference = <0x08>;
					};

					SIDMappings_2 {
						InputBase = <0x3000002>;
						NumIDs = <0x01>;
						OutputBase = <0x4a2>;
						Flags = <0x00>;
						OutputReference = <0x08>;
					};

					SIDMappings_3 {
						InputBase = <0x3000003>;
						NumIDs = <0x01>;
						OutputBase = <0x4a3>;
						Flags = <0x00>;
						OutputReference = <0x08>;
					};

					SIDMappings_4 {
						InputBase = <0x3000004>;
						NumIDs = <0x01>;
						OutputBase = <0x4a4>;
						Flags = <0x00>;
						OutputReference = <0x08>;
					};
				};
			};

			NAMEDNODE_LPASS {
				Type = <0x01>;
				Revision = <0x01>;
				Reserved = <0x00>;
				NumberofMappings = <0x0e>;
				NodeFlags = <0x00>;
				CacheCoherency = <0x00>;
				AllocationHints = <0x00>;
				Reserved1 = <0x00>;
				MemAccessFlags = <0x00>;
				DeviceMemAddressSize = <0x24>;
				DevObjectName = "LPASS";

				SIDMappings {

					SIDMappings_1 {
						InputBase = <0x3000001>;
						NumIDs = <0x01>;
						OutputBase = <0x801001>;
						Flags = <0x00>;
						OutputReference = <0x08>;
					};

					SIDMappings_2 {
						InputBase = <0x3000002>;
						NumIDs = <0x01>;
						OutputBase = <0x801003>;
						Flags = <0x00>;
						OutputReference = <0x08>;
					};

					SIDMappings_3 {
						InputBase = <0x3000003>;
						NumIDs = <0x01>;
						OutputBase = <0x801004>;
						Flags = <0x00>;
						OutputReference = <0x08>;
					};

					SIDMappings_4 {
						InputBase = <0x3000004>;
						NumIDs = <0x01>;
						OutputBase = <0x801005>;
						Flags = <0x00>;
						OutputReference = <0x08>;
					};

					SIDMappings_5 {
						InputBase = <0x3000005>;
						NumIDs = <0x01>;
						OutputBase = <0x801006>;
						Flags = <0x00>;
						OutputReference = <0x08>;
					};

					SIDMappings_6 {
						InputBase = <0x3000006>;
						NumIDs = <0x01>;
						OutputBase = <0x401007>;
						Flags = <0x00>;
						OutputReference = <0x08>;
					};

					SIDMappings_7 {
						InputBase = <0x3000007>;
						NumIDs = <0x01>;
						OutputBase = <0x100b>;
						Flags = <0x00>;
						OutputReference = <0x08>;
					};

					SIDMappings_14 {
						InputBase = <0x300000e>;
						NumIDs = <0x01>;
						OutputBase = <0x201041>;
						Flags = <0x00>;
						OutputReference = <0x08>;
					};

					SIDMappings_15 {
						InputBase = <0x300000f>;
						NumIDs = <0x01>;
						OutputBase = <0x201043>;
						Flags = <0x00>;
						OutputReference = <0x08>;
					};

					SIDMappings_16 {
						InputBase = <0x3000010>;
						NumIDs = <0x01>;
						OutputBase = <0x201044>;
						Flags = <0x00>;
						OutputReference = <0x08>;
					};

					SIDMappings_17 {
						InputBase = <0x3000011>;
						NumIDs = <0x01>;
						OutputBase = <0x201045>;
						Flags = <0x00>;
						OutputReference = <0x08>;
					};

					SIDMappings_18 {
						InputBase = <0x3000012>;
						NumIDs = <0x01>;
						OutputBase = <0x201046>;
						Flags = <0x00>;
						OutputReference = <0x08>;
					};

					SIDMappings_19 {
						InputBase = <0x3000013>;
						NumIDs = <0x01>;
						OutputBase = <0x1067>;
						Flags = <0x00>;
						OutputReference = <0x08>;
					};

					SIDMappings_22 {
						InputBase = <0x3000016>;
						NumIDs = <0x01>;
						OutputBase = <0x1087>;
						Flags = <0x00>;
						OutputReference = <0x08>;
					};
				};
			};

			NAMEDNODE_PCIE0 {
				Type = <0x01>;
				Revision = <0x01>;
				Reserved = <0x00>;
				NumberofMappings = <0x06>;
				NodeFlags = <0x00>;
				CacheCoherency = <0x00>;
				AllocationHints = <0x00>;
				Reserved1 = <0x00>;
				MemAccessFlags = <0x00>;
				DeviceMemAddressSize = <0x24>;
				DevObjectName = "PCIE0";

				SIDMappings {

					SIDMappings_0 {
						InputBase = <0x3000000>;
						NumIDs = <0x01>;
						OutputBase = <0x11400>;
						Flags = <0x00>;
						OutputReference = <0x08>;
					};

					SIDMappings_3 {
						InputBase = <0x3000003>;
						NumIDs = <0x01>;
						OutputBase = <0x31404>;
						Flags = <0x00>;
						OutputReference = <0x08>;
					};

					SIDMappings_4 {
						InputBase = <0x3000004>;
						NumIDs = <0x01>;
						OutputBase = <0x71408>;
						Flags = <0x00>;
						OutputReference = <0x08>;
					};

					SIDMappings_5 {
						InputBase = <0x3000005>;
						NumIDs = <0x01>;
						OutputBase = <0xf1410>;
						Flags = <0x00>;
						OutputReference = <0x08>;
					};

					SIDMappings_6 {
						InputBase = <0x3000006>;
						NumIDs = <0x01>;
						OutputBase = <0x1f1420>;
						Flags = <0x00>;
						OutputReference = <0x08>;
					};

					SIDMappings_7 {
						InputBase = <0x3000007>;
						NumIDs = <0x01>;
						OutputBase = <0x3f1440>;
						Flags = <0x00>;
						OutputReference = <0x08>;
					};
				};
			};

			NAMEDNODE_QDSS {
				Type = <0x01>;
				Revision = <0x01>;
				Reserved = <0x00>;
				NumberofMappings = <0x02>;
				NodeFlags = <0x00>;
				CacheCoherency = <0x00>;
				AllocationHints = <0x00>;
				Reserved1 = <0x00>;
				MemAccessFlags = <0x00>;
				DeviceMemAddressSize = <0x24>;
				DevObjectName = "QDSS";

				SIDMappings {

					SIDMappings_0 {
						InputBase = <0x3000000>;
						NumIDs = <0x01>;
						OutputBase = <0x4e0>;
						Flags = <0x00>;
						OutputReference = <0x08>;
					};

					SIDMappings_1 {
						InputBase = <0x3000001>;
						NumIDs = <0x01>;
						OutputBase = <0x500>;
						Flags = <0x00>;
						OutputReference = <0x08>;
					};
				};
			};

			NAMEDNODE_QUP1 {
				Type = <0x01>;
				Revision = <0x01>;
				Reserved = <0x00>;
				NumberofMappings = <0x03>;
				NodeFlags = <0x00>;
				CacheCoherency = <0x00>;
				AllocationHints = <0x00>;
				Reserved1 = <0x00>;
				MemAccessFlags = <0x00>;
				DeviceMemAddressSize = <0x24>;
				DevObjectName = "QUP1";

				SIDMappings {

					SIDMappings_1 {
						InputBase = <0x3000001>;
						NumIDs = <0x01>;
						OutputBase = <0xb6>;
						Flags = <0x00>;
						OutputReference = <0x08>;
					};

					SIDMappings_2 {
						InputBase = <0x3000002>;
						NumIDs = <0x01>;
						OutputBase = <0xb8>;
						Flags = <0x00>;
						OutputReference = <0x08>;
					};

					SIDMappings_4 {
						InputBase = <0x3000004>;
						NumIDs = <0x01>;
						OutputBase = <0xa3>;
						Flags = <0x00>;
						OutputReference = <0x08>;
					};
				};
			};

			NAMEDNODE_QUP2 {
				Type = <0x01>;
				Revision = <0x01>;
				Reserved = <0x00>;
				NumberofMappings = <0x03>;
				NodeFlags = <0x00>;
				CacheCoherency = <0x00>;
				AllocationHints = <0x00>;
				Reserved1 = <0x00>;
				MemAccessFlags = <0x00>;
				DeviceMemAddressSize = <0x24>;
				DevObjectName = "QUP2";

				SIDMappings {

					SIDMappings_1 {
						InputBase = <0x3000001>;
						NumIDs = <0x01>;
						OutputBase = <0x436>;
						Flags = <0x00>;
						OutputReference = <0x08>;
					};

					SIDMappings_2 {
						InputBase = <0x3000002>;
						NumIDs = <0x01>;
						OutputBase = <0x438>;
						Flags = <0x00>;
						OutputReference = <0x08>;
					};

					SIDMappings_4 {
						InputBase = <0x3000004>;
						NumIDs = <0x01>;
						OutputBase = <0x423>;
						Flags = <0x00>;
						OutputReference = <0x08>;
					};
				};
			};

			NAMEDNODE_SDC2 {
				Type = <0x01>;
				Revision = <0x01>;
				Reserved = <0x00>;
				NumberofMappings = <0x01>;
				NodeFlags = <0x00>;
				CacheCoherency = <0x00>;
				AllocationHints = <0x00>;
				Reserved1 = <0x00>;
				MemAccessFlags = <0x00>;
				DeviceMemAddressSize = <0x24>;
				DevObjectName = "SDC2";

				SIDMappings {

					SIDMappings_0 {
						InputBase = <0x3000000>;
						NumIDs = <0x01>;
						OutputBase = <0x140>;
						Flags = <0x00>;
						OutputReference = <0x08>;
					};
				};
			};

			NAMEDNODE_Sensors {
				Type = <0x01>;
				Revision = <0x01>;
				Reserved = <0x00>;
				NumberofMappings = <0x02>;
				NodeFlags = <0x00>;
				CacheCoherency = <0x00>;
				AllocationHints = <0x00>;
				Reserved1 = <0x00>;
				MemAccessFlags = <0x00>;
				DeviceMemAddressSize = <0x24>;
				DevObjectName = "SENSORS";

				SIDMappings {

					SIDMappings_3 {
						InputBase = <0x3000003>;
						NumIDs = <0x01>;
						OutputBase = <0x10c3>;
						Flags = <0x00>;
						OutputReference = <0x08>;
					};

					SIDMappings_4 {
						InputBase = <0x3000004>;
						NumIDs = <0x01>;
						OutputBase = <0x10d6>;
						Flags = <0x00>;
						OutputReference = <0x08>;
					};
				};
			};

			NAMEDNODE_UFS_95MEM {
				Type = <0x01>;
				Revision = <0x01>;
				Reserved = <0x00>;
				NumberofMappings = <0x01>;
				NodeFlags = <0x00>;
				CacheCoherency = <0x00>;
				AllocationHints = <0x00>;
				Reserved1 = <0x00>;
				MemAccessFlags = <0x00>;
				DeviceMemAddressSize = <0x24>;
				DevObjectName = "UFS_MEM";

				SIDMappings {

					SIDMappings_0 {
						InputBase = <0x3000000>;
						NumIDs = <0x01>;
						OutputBase = <0x60>;
						Flags = <0x00>;
						OutputReference = <0x08>;
					};
				};
			};

			NAMEDNODE_USB3 {
				Type = <0x01>;
				Revision = <0x01>;
				Reserved = <0x00>;
				NumberofMappings = <0x01>;
				NodeFlags = <0x00>;
				CacheCoherency = <0x00>;
				AllocationHints = <0x00>;
				Reserved1 = <0x00>;
				MemAccessFlags = <0x00>;
				DeviceMemAddressSize = <0x24>;
				DevObjectName = "USB3";

				SIDMappings {

					SIDMappings_0 {
						InputBase = <0x3000000>;
						NumIDs = <0x01>;
						OutputBase = <0x40>;
						Flags = <0x00>;
						OutputReference = <0x08>;
					};
				};
			};

			NAMEDNODE_Video {
				Type = <0x01>;
				Revision = <0x01>;
				Reserved = <0x00>;
				NumberofMappings = <0x05>;
				NodeFlags = <0x00>;
				CacheCoherency = <0x00>;
				AllocationHints = <0x00>;
				Reserved1 = <0x00>;
				MemAccessFlags = <0x00>;
				DeviceMemAddressSize = <0x24>;
				DevObjectName = "VIDEO";

				SIDMappings {

					SIDMappings_0 {
						InputBase = <0x3000000>;
						NumIDs = <0x01>;
						OutputBase = <0x1940>;
						Flags = <0x00>;
						OutputReference = <0x08>;
					};

					SIDMappings_1 {
						InputBase = <0x3000001>;
						NumIDs = <0x01>;
						OutputBase = <0x41941>;
						Flags = <0x00>;
						OutputReference = <0x08>;
					};

					SIDMappings_3 {
						InputBase = <0x3000003>;
						NumIDs = <0x01>;
						OutputBase = <0x1943>;
						Flags = <0x00>;
						OutputReference = <0x08>;
					};

					SIDMappings_4 {
						InputBase = <0x3000004>;
						NumIDs = <0x01>;
						OutputBase = <0x1944>;
						Flags = <0x00>;
						OutputReference = <0x08>;
					};

					SIDMappings_5 {
						InputBase = <0x3000005>;
						NumIDs = <0x01>;
						OutputBase = <0x1947>;
						Flags = <0x00>;
						OutputReference = <0x08>;
					};
				};
			};
		};

		sdc1@8804000 {
			compatible = "qcom,sdcc";
			reg = <0x8804000 0x1000>;
			EnableLogging = [00];
			DriveStrength = <0x1fe4>;
			MaxSpeedMode = [05];
			pinctrl-names = "active";
			pinctrl-0 = <0x0a>;
			phandle = <0x17>;

			HsrSettings {
				DLLConfig = <0x7442c>;
				DLLConfig3 = <0x08>;
				DLLTestCtrl = <0x1800000>;
				DDRConfig = <0x80040868>;
				DLLUserCtrl = <0x90106c0>;
				DLLConfig2 = <0x5400>;

				SDR104 {
					DLLConfig2 = <0xa800>;
					DLLConfig3 = <0x10>;
				};

				SDR50 {
					DLLConfig2 = <0x5400>;
					DLLConfig3 = <0x08>;
				};
			};
		};

		usb0 {
			compatible = "qcom,usb";

			hs_phy_cfg {
				table = <0xffffffff 0x00 0xffffffff 0x00 0xffffffff 0x00 0xffffffff 0x00>;
			};

			ss_phy_cfg {
				table = <0x88e8008 0x01 0x88e9c40 0x01 0x88e9000 0xc0 0x88e9004 0x01 0x88e9010 0x02 0x88e9014 0x16 0x88e9018 0x36 0x88e901c 0x04 0x88e9020 0x16 0x88e9024 0x41 0x88e9028 0x41 0x88e902c 0x00 0x88e9030 0x55 0x88e9034 0x75 0x88e9038 0x01 0x88e903c 0x01 0x88e9048 0x25 0x88e904c 0x02 0x88e9050 0x5c 0x88e9054 0x0f 0x88e9058 0x5c 0x88e905c 0x0f 0x88e9060 0xc0 0x88e9064 0x01 0x88e9070 0x02 0x88e9074 0x16 0x88e9078 0x36 0x88e9080 0x08 0x88e9084 0x1a 0x88e9088 0x41 0x88e908c 0x00 0x88e9090 0x55 0x88e9094 0x75 0x88e9098 0x01 0x88e90a8 0x25 0x88e90ac 0x02 0x88e90bc 0x0a 0x88e90c0 0x01 0x88e90cc 0x62 0x88e90d0 0x02 0x88e90e8 0x0c 0x88e9110 0x1a 0x88e9124 0x14 0x88e9140 0x04 0x88e9170 0x20 0x88e9174 0x16 0x88e91a4 0xb6 0x88e91a8 0x4b 0x88e91ac 0x37 0x88e91b4 0x0c 0x88e9234 0x00 0x88e9238 0x00 0x88e923c 0x1f 0x88e9240 0x09 0x88e9284 0xf5 0x88e928c 0x3f 0x88e9290 0x3f 0x88e9294 0x5f 0x88e92a4 0x12 0x88e92e4 0x21 0x88e9408 0x0a 0x88e9414 0x06 0x88e9430 0x2f 0x88e9434 0x7f 0x88e943c 0xff 0x88e9440 0x0f 0x88e9444 0x99 0x88e944c 0x08 0x88e9450 0x08 0x88e9454 0x00 0x88e9458 0x0a 0x88e9460 0xa0 0x88e94d4 0x54 0x88e94d8 0x0f 0x88e94dc 0x13 0x88e94ec 0x0f 0x88e94f0 0x4a 0x88e94f4 0x0a 0x88e94f8 0x07 0x88e94fc 0x00 0x88e9510 0x47 0x88e951c 0x04 0x88e9524 0x0e 0x88e955c 0x3f 0x88e9560 0xbf 0x88e9564 0xff 0x88e9568 0xdf 0x88e956c 0xed 0x88e9570 0xdc 0x88e9574 0x5c 0x88e9578 0x9c 0x88e957c 0x1d 0x88e9580 0x09 0x88e95a0 0x04 0x88e95a4 0x38 0x88e95a8 0x0c 0x88e95b0 0x10 0x88e95e4 0x14 0x88e95f8 0x08 0x88e9634 0x00 0x88e9638 0x00 0x88e963c 0x1f 0x88e9640 0x09 0x88e9684 0xf5 0x88e968c 0x3f 0x88e9690 0x3f 0x88e9694 0x5f 0x88e96a4 0x12 0x88e96e4 0x05 0x88e9808 0x0a 0x88e9814 0x06 0x88e9830 0x2f 0x88e9834 0x7f 0x88e983c 0xff 0x88e9840 0x0f 0x88e9844 0x99 0x88e984c 0x08 0x88e9850 0x08 0x88e9854 0x00 0x88e9858 0x0a 0x88e9860 0xa0 0x88e98d4 0x54 0x88e98d8 0x0f 0x88e98dc 0x13 0x88e98ec 0x0f 0x88e98f0 0x4a 0x88e98f4 0x0a 0x88e98f8 0x07 0x88e98fc 0x00 0x88e9910 0x47 0x88e991c 0x04 0x88e9924 0x0e 0x88e995c 0xbf 0x88e9960 0xbf 0x88e9964 0xbf 0x88e9968 0xdf 0x88e996c 0xfd 0x88e9970 0xdc 0x88e9974 0x5c 0x88e9978 0x9c 0x88e997c 0x1d 0x88e9980 0x09 0x88e99a0 0x04 0x88e99a4 0x38 0x88e99a8 0x0c 0x88e99b0 0x10 0x88e99e4 0x14 0x88e99f8 0x08 0x88e9cc4 0xc4 0x88e9cc8 0x89 0x88e9ccc 0x20 0x88e9cd8 0x13 0x88e9cdc 0x21 0x88e9d88 0x99 0x88e9d90 0xe7 0x88e9d94 0x03 0x88e9db0 0x0a 0x88e9dc0 0x88 0x88e9dc4 0x13 0x88e9dd0 0x0c 0x88e9ddc 0x4b 0x88e9dec 0x10 0x88e9f00 0x68 0x88e9f18 0xf8 0x88e9f3c 0x07 0x88e9f40 0x40 0x88e9f44 0x00 0x00 0x00>;
			};
		};

		ssr {
			compatible = "qcom,ssr";
			max_subsys_configured = <0x04>;

			smp2p_err_fatal {
				entry_name = "slave-kernel";
				bit = <0x00>;
				phandle = <0x0b>;
			};

			smp2p_err_ready {
				entry_name = "slave-kernel";
				bit = <0x01>;
				phandle = <0x0d>;
			};

			smp2p_proxy_unvote {
				entry_name = "slave-kernel";
				bit = <0x02>;
				phandle = <0x0c>;
			};

			smp2p_stop_ack {
				entry_name = "slave-kernel";
				bit = <0x03>;
				phandle = <0x0e>;
			};

			ssr_subsys_config_1 {
				subsys_name = "lpass";
				subsys_id = <0x01>;
				host = <0x02>;
				sfr_type = <0x1a7>;
				wdog_intr = <0x206 0x00>;
				err_fatal = <0x0b>;
				proxy_unvote = <0x0c>;
				err_ready = <0x0d>;
				stop_ack_bit = <0x0e>;
				qmi_svc_ins = <0x14>;
			};

			ssr_subsys_config_2 {
				subsys_name = "cdsp";
				subsys_id = <0x12>;
				host = <0x05>;
				sfr_type = <0x259>;
				wdog_intr = <0x262 0x00>;
				err_fatal = <0x0b>;
				proxy_unvote = <0x0c>;
				err_ready = <0x0d>;
				stop_ack_bit = <0x0e>;
				qmi_svc_ins = <0x17>;
			};

			ssr_subsys_config_3 {
				subsys_name = "mpss";
				subsys_id = <0x04>;
				host = <0x01>;
				sfr_type = <0x1a5>;
				wdog_intr = <0x128 0x00>;
				err_fatal = <0x0b>;
				proxy_unvote = <0x0c>;
				err_ready = <0x0d>;
				stop_ack_bit = <0x0e>;
				qmi_svc_ins = <0x12>;
			};

			ssr_subsys_config_4 {
				subsys_name = "wpss";
				subsys_id = <0x06>;
				host = <0x0d>;
				sfr_type = <0x272>;
				wdog_intr = <0xe8 0x00>;
				err_fatal = <0x0b>;
				proxy_unvote = <0x0c>;
				err_ready = <0x0d>;
				stop_ack_bit = <0x0e>;
				qmi_svc_ins = <0x19>;
			};
		};

		memorymap {
			compatible = "qcom,uefimem";
			#address-cells = <0x02>;
			#size-cells = <0x02>;

			memory@80000000 {
				device_type = "memory";
				reg = <0x00 0x80000000 0x00 0x16e0000>;
				MemLabel = "NOMAP";
				ResourceAttribute = <0x400>;
				BuildHob = [09];
				ResourceType = [05];
				MemoryType = [00];
				CacheAttributes = [25];
			};

			memory@816E0000 {
				device_type = "memory";
				reg = <0x00 0x816e0000 0x00 0x320000>;
				MemLabel = "RSRV0";
				ResourceAttribute = <0x703c07>;
				BuildHob = [00];
				ResourceType = [00];
				MemoryType = [00];
				CacheAttributes = [22];
			};

			memory@81A00000 {
				device_type = "memory";
				reg = <0x00 0x81a00000 0x00 0x40000>;
				MemLabel = "XBL_DT";
				ResourceAttribute = <0x703c07>;
				BuildHob = [00];
				ResourceType = [05];
				MemoryType = [00];
				CacheAttributes = [22];
			};

			memory@81A40000 {
				device_type = "memory";
				reg = <0x00 0x81a40000 0x00 0x1c0000>;
				MemLabel = "XBL_Ramdump";
				ResourceAttribute = <0x400>;
				BuildHob = [00];
				ResourceType = [05];
				MemoryType = [00];
				CacheAttributes = [25];
			};

			memory@81C00000 {
				device_type = "memory";
				reg = <0x00 0x81c00000 0x00 0xa0000>;
				MemLabel = "AOP";
				ResourceAttribute = <0x400>;
				BuildHob = [00];
				ResourceType = [05];
				MemoryType = [00];
				CacheAttributes = [25];
			};

			memory@81CE4000 {
				device_type = "memory";
				reg = <0x00 0x81ce4000 0x00 0x10000>;
				MemLabel = "UEFI_Log";
				ResourceAttribute = <0x400>;
				BuildHob = [00];
				ResourceType = [05];
				MemoryType = [00];
				CacheAttributes = [25];
			};

			memory@81D00000 {
				device_type = "memory";
				reg = <0x00 0x81d00000 0x00 0x200000>;
				MemLabel = "SMEM";
				ResourceAttribute = <0x400>;
				BuildHob = [00];
				ResourceType = [05];
				MemoryType = [00];
				CacheAttributes = [25];
			};

			memory@824A0000 {
				device_type = "memory";
				reg = <0x00 0x824a0000 0x00 0x100000>;
				MemLabel = "PvmFw";
				ResourceAttribute = <0x703c07>;
				BuildHob = [00];
				ResourceType = [00];
				MemoryType = [00];
				CacheAttributes = [22];
			};

			memory@8BC00000 {
				device_type = "memory";
				reg = <0x00 0x8bc00000 0x00 0x16e00000>;
				MemLabel = "PIL_Reserved";
				ResourceAttribute = <0x400>;
				BuildHob = [00];
				ResourceType = [05];
				MemoryType = [00];
				CacheAttributes = [25];
			};

			memory@A2A00000 {
				device_type = "memory";
				reg = <0x00 0xa2a00000 0x00 0xf00000>;
				MemLabel = "DBI_Dump";
				ResourceAttribute = <0x02>;
				BuildHob = [04];
				ResourceType = [01];
				MemoryType = [07];
				CacheAttributes = [25];
			};

			memory@A7000000 {
				device_type = "memory";
				reg = <0x00 0xa7000000 0x00 0x400000>;
				MemLabel = "UEFI_FD";
				ResourceAttribute = <0x703c07>;
				BuildHob = [00];
				ResourceType = [00];
				MemoryType = [04];
				CacheAttributes = [02];
			};

			memory@A7400000 {
				device_type = "memory";
				reg = <0x00 0xa7400000 0x00 0x200000>;
				MemLabel = "UEFI_FD_Reserved";
				ResourceAttribute = <0x703c07>;
				BuildHob = [00];
				ResourceType = [00];
				MemoryType = [04];
				CacheAttributes = [02];
			};

			memory@A7600000 {
				device_type = "memory";
				reg = <0x00 0xa7600000 0x00 0x1000>;
				MemLabel = "CPU_Vectors";
				ResourceAttribute = <0x703c07>;
				BuildHob = [00];
				ResourceType = [00];
				MemoryType = [04];
				CacheAttributes = [02];
			};

			memory@A7601000 {
				device_type = "memory";
				reg = <0x00 0xa7601000 0x00 0x1000>;
				MemLabel = "Info_Blk";
				ResourceAttribute = <0x703c07>;
				BuildHob = [00];
				ResourceType = [00];
				MemoryType = [06];
				CacheAttributes = [22];
			};

			memory@A7602000 {
				device_type = "memory";
				reg = <0x00 0xa7602000 0x00 0x3000>;
				MemLabel = "MMU_PageTables";
				ResourceAttribute = <0x703c07>;
				BuildHob = [00];
				ResourceType = [00];
				MemoryType = [04];
				CacheAttributes = [22];
			};

			memory@A7605000 {
				device_type = "memory";
				reg = <0x00 0xa7605000 0x00 0x8000>;
				MemLabel = "Log_Buffer";
				ResourceAttribute = <0x703c07>;
				BuildHob = [00];
				ResourceType = [00];
				MemoryType = [06];
				CacheAttributes = [22];
			};

			memory@A760D000 {
				device_type = "memory";
				reg = <0x00 0xa760d000 0x00 0x40000>;
				MemLabel = "UEFI_Stack";
				ResourceAttribute = <0x703c07>;
				BuildHob = [00];
				ResourceType = [00];
				MemoryType = [04];
				CacheAttributes = [22];
			};

			memory@A764D000 {
				device_type = "memory";
				reg = <0x00 0xa764d000 0x00 0x8c000>;
				MemLabel = "SEC_Heap";
				ResourceAttribute = <0x703c07>;
				BuildHob = [00];
				ResourceType = [00];
				MemoryType = [04];
				CacheAttributes = [22];
			};

			memory@A76D9000 {
				device_type = "memory";
				reg = <0x00 0xa76d9000 0x00 0x400000>;
				MemLabel = "Sched_Heap";
				ResourceAttribute = <0x703c07>;
				BuildHob = [00];
				ResourceType = [00];
				MemoryType = [04];
				CacheAttributes = [22];
			};

			memory@A7AD9000 {
				device_type = "memory";
				reg = <0x00 0xa7ad9000 0x00 0x400000>;
				MemLabel = "FV_Region";
				ResourceAttribute = <0x703c07>;
				BuildHob = [00];
				ResourceType = [00];
				MemoryType = [04];
				CacheAttributes = [22];
			};

			memory@A7ED9000 {
				device_type = "memory";
				reg = <0x00 0xa7ed9000 0x00 0x127000>;
				MemLabel = "UEFI_RESV";
				ResourceAttribute = <0x703c07>;
				BuildHob = [00];
				ResourceType = [00];
				MemoryType = [04];
				CacheAttributes = [22];
			};

			memory@A8000000 {
				device_type = "memory";
				reg = <0x00 0xa8000000 0x00 0x10000000>;
				MemLabel = "Kernel";
				ResourceAttribute = <0x703c07>;
				BuildHob = [00];
				ResourceType = [00];
				MemoryType = [00];
				CacheAttributes = [22];
			};

			memory@B8000000 {
				device_type = "memory";
				reg = <0x00 0xb8000000 0x00 0x1ba00000>;
				MemLabel = "DXE_Heap";
				ResourceAttribute = <0x703c07>;
				BuildHob = [00];
				ResourceType = [00];
				MemoryType = [07];
				CacheAttributes = [22];
			};

			memory@D3A00000 {
				device_type = "memory";
				reg = <0x00 0xd3a00000 0x00 0x2b00000>;
				MemLabel = "Display_Demura";
				ResourceAttribute = <0x703c07>;
				BuildHob = [00];
				ResourceType = [05];
				MemoryType = [00];
				CacheAttributes = [20];
			};

			memory@D8800000 {
				device_type = "memory";
				reg = <0x00 0xd8800000 0x00 0x93b0000>;
				MemLabel = "TZApps_Reserved";
				ResourceAttribute = <0x400>;
				BuildHob = [0a];
				ResourceType = [05];
				MemoryType = [00];
				CacheAttributes = [25];
			};

			memory@E3940000 {
				device_type = "memory";
				reg = <0x00 0xe3940000 0x00 0x2b00000>;
				MemLabel = "Display_Reserved";
				ResourceAttribute = <0x703c07>;
				BuildHob = [00];
				ResourceType = [05];
				MemoryType = [00];
				CacheAttributes = [20];
			};

			memory@E6440000 {
				device_type = "memory";
				reg = <0x00 0xe6440000 0x00 0xcdc0000>;
				MemLabel = "DXE_Heap1";
				ResourceAttribute = <0x703c07>;
				BuildHob = [00];
				ResourceType = [00];
				MemoryType = [07];
				CacheAttributes = [22];
			};
		};

		registermap {
			compatible = "qcom,uefimem";
			#address-cells = <0x02>;
			#size-cells = <0x02>;

			memory@14680000 {
				device_type = "memory";
				reg = <0x00 0x14680000 0x00 0x2a000>;
				MemLabel = "IMEM_Base";
				ResourceAttribute = <0x02>;
				BuildHob = [04];
				ResourceType = [01];
				MemoryType = [07];
				CacheAttributes = [09];
			};

			memory@146AA000 {
				device_type = "memory";
				reg = <0x00 0x146aa000 0x00 0x16000>;
				MemLabel = "IMEM_Cookie_Base";
				ResourceAttribute = <0x02>;
				BuildHob = [05];
				ResourceType = [01];
				MemoryType = [07];
				CacheAttributes = [09];
			};

			memory@400000 {
				device_type = "memory";
				reg = <0x00 0x400000 0x00 0x100000>;
				MemLabel = "IPC_ROUTER_TOP";
				ResourceAttribute = <0x400>;
				BuildHob = [05];
				ResourceType = [01];
				MemoryType = [0b];
				CacheAttributes = [09];
			};

			memory@780000 {
				device_type = "memory";
				reg = <0x00 0x780000 0x00 0x7000>;
				MemLabel = "SECURITY_CONTROL";
				ResourceAttribute = <0x400>;
				BuildHob = [05];
				ResourceType = [01];
				MemoryType = [0b];
				CacheAttributes = [09];
			};

			memory@800000 {
				device_type = "memory";
				reg = <0x00 0x800000 0x00 0x300000>;
				MemLabel = "QUP";
				ResourceAttribute = <0x400>;
				BuildHob = [05];
				ResourceType = [01];
				MemoryType = [0b];
				CacheAttributes = [09];
			};

			memory@10C0000 {
				device_type = "memory";
				reg = <0x00 0x10c0000 0x00 0xc000>;
				MemLabel = "PRNG_CFG_PRNG";
				ResourceAttribute = <0x400>;
				BuildHob = [05];
				ResourceType = [01];
				MemoryType = [0b];
				CacheAttributes = [09];
			};

			memory@1DC0000 {
				device_type = "memory";
				reg = <0x00 0x1dc0000 0x00 0x40000>;
				MemLabel = "CRYPTO0_CRYPTO";
				ResourceAttribute = <0x400>;
				BuildHob = [05];
				ResourceType = [01];
				MemoryType = [0b];
				CacheAttributes = [09];
			};

			memory@1F00000 {
				device_type = "memory";
				reg = <0x00 0x1f00000 0x00 0x100000>;
				MemLabel = "CLK_TCSR_TCSR_REGS";
				ResourceAttribute = <0x400>;
				BuildHob = [05];
				ResourceType = [01];
				MemoryType = [0b];
				CacheAttributes = [09];
			};

			memory@8800000 {
				device_type = "memory";
				reg = <0x00 0x8800000 0x00 0x100000>;
				MemLabel = "PERIPH_SS";
				ResourceAttribute = <0x400>;
				BuildHob = [05];
				ResourceType = [01];
				MemoryType = [0b];
				CacheAttributes = [09];
			};

			memory@A600000 {
				device_type = "memory";
				reg = <0x00 0xa600000 0x00 0x200000>;
				MemLabel = "USB";
				ResourceAttribute = <0x400>;
				BuildHob = [05];
				ResourceType = [01];
				MemoryType = [0b];
				CacheAttributes = [09];
			};

			memory@B000000 {
				device_type = "memory";
				reg = <0x00 0xb000000 0x00 0x4000000>;
				MemLabel = "AOSS";
				ResourceAttribute = <0x400>;
				BuildHob = [05];
				ResourceType = [01];
				MemoryType = [0b];
				CacheAttributes = [09];
			};

			memory@F000000 {
				device_type = "memory";
				reg = <0x00 0xf000000 0x00 0x1000000>;
				MemLabel = "TLMM";
				ResourceAttribute = <0x400>;
				BuildHob = [05];
				ResourceType = [01];
				MemoryType = [0b];
				CacheAttributes = [09];
			};

			memory@15000000 {
				device_type = "memory";
				reg = <0x00 0x15000000 0x00 0x200000>;
				MemLabel = "SMMU";
				ResourceAttribute = <0x400>;
				BuildHob = [05];
				ResourceType = [01];
				MemoryType = [0b];
				CacheAttributes = [09];
			};

			memory@17000000 {
				device_type = "memory";
				reg = <0x00 0x17000000 0x00 0x2000000>;
				MemLabel = "APSS_HM";
				ResourceAttribute = <0x400>;
				BuildHob = [05];
				ResourceType = [01];
				MemoryType = [0b];
				CacheAttributes = [09];
			};
		};

		systemcache {
			compatible = "qcom,systemcache";
			llcc_broadcast_trp_offset = <0x1a00000>;
			scid_attr0_reserved_ways_bmsk = <0x3fff>;
			scid_attr0_reserved_ways_shft = <0x00>;
			scid_attr2_bonus_ways_bmsk = <0x3fff>;
			scid_attr2_bonus_ways_shft = <0x00>;
			llcc_channel_offsets = <0x1000000 0x1400000 0x1200000 0x1600000>;
			num_sct_tables = <0x01>;

			sct_table_1 {

				sct_table_entry_0 {
					usecase_id = <0x00>;
					scid = <0x00>;
					max_capacity = <0x00>;
					priority = <0x00>;
					bonus_ways = <0x00>;
					reserved_ways = <0x00>;
					cache_mode = <0x00>;
					fixedsize = <0x01>;
					dis_capacity_alloc = <0x00>;
					write_scid_en = <0x00>;
					write_scid_cacheable_en = <0x00>;
					algo_cfg = <0x00>;
					activate_at_boot = <0x00>;
				};

				sct_table_entry_1 {
					usecase_id = <0x01>;
					scid = <0x01>;
					max_capacity = <0xc80>;
					priority = <0x00>;
					bonus_ways = <0x3fff>;
					reserved_ways = <0x00>;
					cache_mode = <0x00>;
					fixedsize = <0x00>;
					dis_capacity_alloc = <0x00>;
					write_scid_en = <0x00>;
					write_scid_cacheable_en = <0x00>;
					algo_cfg = <0x00>;
					activate_at_boot = <0x01>;
				};

				sct_table_entry_2 {
					usecase_id = <0x02>;
					scid = <0x02>;
					max_capacity = <0x80>;
					priority = <0x03>;
					bonus_ways = <0x3fff>;
					reserved_ways = <0x00>;
					cache_mode = <0x00>;
					fixedsize = <0x01>;
					dis_capacity_alloc = <0x00>;
					write_scid_en = <0x00>;
					write_scid_cacheable_en = <0x00>;
					algo_cfg = <0x00>;
					activate_at_boot = <0x00>;
				};

				sct_table_entry_3 {
					usecase_id = <0x07>;
					scid = <0x19>;
					max_capacity = <0x400>;
					priority = <0x03>;
					bonus_ways = <0x3fff>;
					reserved_ways = <0x00>;
					cache_mode = <0x00>;
					fixedsize = <0x00>;
					dis_capacity_alloc = <0x00>;
					write_scid_en = <0x00>;
					write_scid_cacheable_en = <0x00>;
					algo_cfg = <0x00>;
					activate_at_boot = <0x00>;
				};

				sct_table_entry_4 {
					usecase_id = <0x0b>;
					scid = <0x0b>;
					max_capacity = <0x100>;
					priority = <0x01>;
					bonus_ways = <0x3fff>;
					reserved_ways = <0x00>;
					cache_mode = <0x00>;
					fixedsize = <0x01>;
					dis_capacity_alloc = <0x00>;
					write_scid_en = <0x00>;
					write_scid_cacheable_en = <0x00>;
					algo_cfg = <0x00>;
					activate_at_boot = <0x00>;
				};

				sct_table_entry_5 {
					usecase_id = <0x0c>;
					scid = <0x09>;
					max_capacity = <0xa80>;
					priority = <0x01>;
					bonus_ways = <0x3fff>;
					reserved_ways = <0x00>;
					cache_mode = <0x00>;
					fixedsize = <0x00>;
					dis_capacity_alloc = <0x00>;
					write_scid_en = <0x01>;
					write_scid_cacheable_en = <0x00>;
					algo_cfg = <0x00>;
					activate_at_boot = <0x00>;
				};

				sct_table_entry_6 {
					usecase_id = <0x0d>;
					scid = <0x12>;
					max_capacity = <0x200>;
					priority = <0x01>;
					bonus_ways = <0x3fff>;
					reserved_ways = <0x00>;
					cache_mode = <0x00>;
					fixedsize = <0x01>;
					dis_capacity_alloc = <0x00>;
					write_scid_en = <0x00>;
					write_scid_cacheable_en = <0x00>;
					algo_cfg = <0x00>;
					activate_at_boot = <0x01>;
				};

				sct_table_entry_7 {
					usecase_id = <0x10>;
					scid = <0x10>;
					max_capacity = <0xe00>;
					priority = <0x01>;
					bonus_ways = <0x3fff>;
					reserved_ways = <0x00>;
					cache_mode = <0x02>;
					fixedsize = <0x01>;
					dis_capacity_alloc = <0x00>;
					write_scid_en = <0x00>;
					write_scid_cacheable_en = <0x00>;
					algo_cfg = <0x00>;
					activate_at_boot = <0x00>;
				};

				sct_table_entry_8 {
					usecase_id = <0x14>;
					scid = <0x18>;
					max_capacity = <0x400>;
					priority = <0x03>;
					bonus_ways = <0x3fff>;
					reserved_ways = <0x00>;
					cache_mode = <0x00>;
					fixedsize = <0x01>;
					dis_capacity_alloc = <0x00>;
					write_scid_en = <0x00>;
					write_scid_cacheable_en = <0x00>;
					algo_cfg = <0x00>;
					activate_at_boot = <0x00>;
				};

				sct_table_entry_9 {
					usecase_id = <0x15>;
					scid = <0x1b>;
					max_capacity = <0x100>;
					priority = <0x03>;
					bonus_ways = <0x3fff>;
					reserved_ways = <0x00>;
					cache_mode = <0x00>;
					fixedsize = <0x01>;
					dis_capacity_alloc = <0x00>;
					write_scid_en = <0x00>;
					write_scid_cacheable_en = <0x00>;
					algo_cfg = <0x00>;
					activate_at_boot = <0x00>;
				};

				sct_table_entry_10 {
					usecase_id = <0x1d>;
					scid = <0x1d>;
					max_capacity = <0x40>;
					priority = <0x01>;
					bonus_ways = <0x3c00>;
					reserved_ways = <0x00>;
					cache_mode = <0x00>;
					fixedsize = <0x01>;
					dis_capacity_alloc = <0x00>;
					write_scid_en = <0x00>;
					write_scid_cacheable_en = <0x00>;
					algo_cfg = <0x10>;
					activate_at_boot = <0x00>;
				};

				sct_table_entry_11 {
					usecase_id = <0x1f>;
					scid = <0x1f>;
					max_capacity = <0x100>;
					priority = <0x01>;
					bonus_ways = <0x3fff>;
					reserved_ways = <0x00>;
					cache_mode = <0x00>;
					fixedsize = <0x01>;
					dis_capacity_alloc = <0x00>;
					write_scid_en = <0x00>;
					write_scid_cacheable_en = <0x00>;
					algo_cfg = <0x00>;
					activate_at_boot = <0x01>;
				};

				sct_table_entry_12 {
					usecase_id = <0x22>;
					scid = <0x04>;
					max_capacity = <0x100>;
					priority = <0x03>;
					bonus_ways = <0x0f>;
					reserved_ways = <0x00>;
					cache_mode = <0x00>;
					fixedsize = <0x01>;
					dis_capacity_alloc = <0x00>;
					write_scid_en = <0x00>;
					write_scid_cacheable_en = <0x00>;
					algo_cfg = <0x00>;
					activate_at_boot = <0x00>;
				};

				sct_table_entry_13 {
					usecase_id = <0x26>;
					scid = <0x07>;
					max_capacity = <0x600>;
					priority = <0x02>;
					bonus_ways = <0x3ff0>;
					reserved_ways = <0x00>;
					cache_mode = <0x02>;
					fixedsize = <0x01>;
					dis_capacity_alloc = <0x00>;
					write_scid_en = <0x00>;
					write_scid_cacheable_en = <0x00>;
					algo_cfg = <0x00>;
					activate_at_boot = <0x00>;
				};

				sct_table_entry_14 {
					usecase_id = <0x28>;
					scid = <0x1e>;
					max_capacity = <0x80>;
					priority = <0x03>;
					bonus_ways = <0x3fff>;
					reserved_ways = <0x00>;
					cache_mode = <0x00>;
					fixedsize = <0x01>;
					dis_capacity_alloc = <0x00>;
					write_scid_en = <0x00>;
					write_scid_cacheable_en = <0x00>;
					algo_cfg = <0x10>;
					activate_at_boot = <0x01>;
				};

				sct_table_entry_15 {
					usecase_id = <0x2e>;
					scid = <0x0c>;
					max_capacity = <0xd00>;
					priority = <0x07>;
					bonus_ways = <0x00>;
					reserved_ways = <0x1fff>;
					cache_mode = <0x00>;
					fixedsize = <0x01>;
					dis_capacity_alloc = <0x00>;
					write_scid_en = <0x00>;
					write_scid_cacheable_en = <0x00>;
					algo_cfg = <0x00>;
					activate_at_boot = <0x00>;
				};
			};
		};

		qntm_tz_memmap {
			compatible = "qcom,qntm_tz_memmap";
			#address-cells = <0x02>;
			#size-cells = <0x02>;

			memory@14680000 {
				device_type = "memory";
				reg = <0x00 0x14680000 0x00 0x2c000>;
				MemLabel = "IMEM";
				SharedImemOffset = <0x00>;
				ImemHypOffset = <0xb20>;
				ImemTzDiagOffset = <0x720>;
				SystemImemTzOffset = <0xf000>;
				SystemImemTzSize = <0x19000>;
				TzbspCpuCount = <0x08>;
			};

			memory@80000000 {
				device_type = "memory";
				reg = <0x00 0x80000000 0x00 0x80000000>;
				MemLabel = "DDR";
				SclTzDdrOffset = "X.", "";
				SclTzDdrSize = <0x520000>;
				TzAppsRegionSize = "\t;", "";
			};
		};

		disp_rdump_region@E3940000 {
			compatible = "qcom,display";
			reg = <0xe3940000 0x2b00000>;
			label = "disp_rdump_region";
		};

		text_mode_table {
			table = <0x50 0x19 0x4b 0x2a 0x5a 0x43 0x60 0x35 0x60 0x43 0x60 0x47>;
		};
	};

	sw {
		phandle = <0x18>;

		boot {
			compatible = "qcom,boot";
			config = <0x00 0x00 0x00>;
			force_dump_to_usb = <0x00>;
			test_mode = <0x00>;
			xbl_sc_wdog = <0x01>;
			xbl_ramdump_wdog = <0x00>;
			skip_ddr_init_in_EDL = <0x00>;
			vibration = <0x00>;
			save_logs_to_media = <0x01>;

			forced_download {
				feature = <0x01>;
				check_usb_option = <0x02>;
				check_dp_timeout = <0x2710>;
				ignore_pwr_key = <0x01>;
			};

			fedl_timeout {
				ver = <0x01>;
				action = <0x01>;
			};
		};

		pmic {

			pm {
				phandle = <0x19>;

				pon {
					compatible = "qcom,pm-pon";

					pshold {
						enable = [00];
						reset-type = [01];
					};

					smpl {
						enable = [01];
						smpl-delay = <0x320>;
					};

					s2-kpdpwr {
						enable = [00];
						reset-type = [00];
						s1-ms = <0x2810>;
						s2-ms = <0x7d0>;
					};

					s2-kpdpwr-resin {
						enable = [01];
						reset-type = [01];
						s1-ms = <0x2810>;
						s2-ms = <0x7d0>;
					};

					s2-resin {
						enable = [00];
						reset-type = [01];
						s1-ms = <0x2810>;
						s2-ms = <0x7d0>;
					};

					s3-reset {
						enable = [01];
						s3-src = [02];
						timer-value-ms = <0x3e80>;
					};

					uvlo-config {
						config-value = <0x00>;
					};

					ovlo-config {
						config-value = <0x00>;
					};

					long-pwrkey-dbnc-chk {
						dbnc-time-ms = <0x898>;
						chk-at = [01];
					};
				};

				display {
					compatible = "qcom,pm-display";
					swire-map = [07];
					apply-default-volt = [00];
					default-elvss = <0xfffff060>;
					default-elvdd = <0x11f8>;
					default-oledb = <0x1900>;
				};

				haptics {
					compatible = "qcom,pm-haptics";
					ext-boost-vdd = <0x01>;
					vmax-hdrm = <0x0a>;
					vmax-mv = <0x578>;
					tlra-ol = <0x477>;
					autores-cfg = <0x01>;
					vbatt-min = <0x00>;
					boost-cfg-bob = <0x00>;
					lra-resistance = <0x24>;
					swr-io-volt = <0x00>;
				};

				oplus_vibr {

					vibr_0 {
						support_project = <0x5cfb 0x5d39 0x5d3a 0x5c39 0x606f 0x5c46 0x5ca6 0x5e93 0x5e94 0x60e1>;
						vibr_min_vbatt = <0x1900>;
						vibr_scheme = <0x03>;
						instance = <0x04>;
						reset_gpio = <0x93>;
						device_type = <0x00>;
					};
				};

				charger {
					compatible = "qcom,pm-charger";
					parallel-charger = [00];
					charger-pmic-index = <0x07>;
					charger-bus-index = <0x00>;
					loader-dbc-threshold = <0x00>;
					dbc-sdp-thd-inc = <0x64>;
					skip-loader-dbc = [00];
					core-dbc-threshold = <0x00>;
					skip-core-dbc = [01];
					dbc-max-timer-sec = <0x00>;
					uv-oc-1s-threshold = <0x960>;
					uv-oc-2s-threshold = <0x12c0>;
					apply-ichg-fs = [01];
					ichg-fs = <0x00>;
					batt-2s-option = <0x01>;
					batt-1s2p-id2 = [00];
					batt-1s2p-therm2 = [00];
					too-hot-afp-threshold = <0x48>;
					apply-too-hot-afp = [00];
					too-cold-afp-threshold = <0xfffffff1>;
					apply-too-cold-afp = [00];
					apply-boot-wo-batt = [01];
					boot-wo-batt = [01];
					icl-boot-wo-batt = <0x3e8>;
					apply-float-voltage = [01];
					float-voltage-mv = <0x1176>;
					apply-pre-charge-current = [01];
					pre-charge-ma = <0x258>;
					apply-fast-charge-current = [01];
					fast-charge-ma = <0x258>;
					apply-icl = [01];
					icl-ma = <0x7d0>;
					apply-float-charger-icl = [00];
					float-charger-icl-ma = <0x3e8>;
					apply-vsysmin = [01];
					vsysmin = <0xd48>;
					usb-suspend = [00];
					wls-usb-prior-swap = <0x01>;
					batt-detect-src = <0x00>;
					max-dbg-board-id = <0x2af8>;
					min-dbg-board-id = <0xbb8>;
					detect-jig-by-therm = [00];
					max-therm = <0x30c>;
					min-therm = <0x50>;
					jig-icl-ma = <0x5dc>;
					uvp-recover-delay = <0xbb8>;
					ignore-temp-in-dbc = [01];
					batt-therm-pull-up = <0x01>;
					ibat-via-ext-sense = [01];
					ext-rsns-adc-scale = <0x00>;
					ext-rsns-installed = <0x00>;
					vbat-thd-rtc-pon = <0xe10>;
					vsys-min-recover-mv = <0x11f8>;
					vflt-recover-mv = <0x1194>;
				};

				camera {
					compatible = "qcom,pm-camera";
					rst-signal = <0x07 0x0b>;
				};

				sw-config {
					compatible = "qcom,pm-sw";
					verbose = <0x00>;
					driver-post-init = <0x65 0x00 0x00 0x03 0x03 0x01 0x00 0x0c 0x04 0x708 0x01 0x00 0x01 0x0d 0xbb8 0x01 0x00 0x01 0x0e 0xaf0 0x07 0x00 0x00 0x00 0x01 0x3f 0x00 0x07 0x02 0x01 0x3f 0x00 0x07 0x03 0x01 0x3d 0x00 0x03 0x04 0x01 0x3f 0x00 0x03 0x04 0x01 0x43 0x00 0x03 0x04 0x05 0x3e 0x00 0x03 0x04 0x00 0x3c 0x00 0x03 0x04 0x01 0x64 0x00 0x00 0x00 0x0a>;
					apply-rsns-trim = <0x00>;
					rsns-trim-value = <0x00>;
					primming-enable = [00];
					multi-card-tray-config = [00];
					vdd-mdm-apq-ctrl = [00];
					device-pre-init = <0x85 0x00 0x00 0x00 0x00>;
					use-wlan-dt = [00];
					batt-log-param = [00];
				};
			};

			psi {
				compatible = "qcom,pm-psi";
				phandle = <0x1a>;

				pm-psi-variant {
					major = [00 00];
					minor = [00 00];
				};

				pm-psi-clogic {
					clogic-version = <0x01>;
					clogic-data = <0x00 0x00 0x00 0x10 0xff 0x52 0x01>;
				};

				pm-psi-seq {
					opsi-settings-version = <0x01>;
					post-device-opsi = <0x00 0x00 0x04 0x00 0x00 0x00 0x00 0x00 0x00>;
				};
			};

			adc {
				phandle = <0x1b>;

				vadc {
					phandle = <0x1c>;

					spmi-vadc {
						compatible = "qcom,spmi-vadc";
						use-interrupt = <0x00>;
						fullscale-code = <0x70e4>;
						fullscale-uV = <0x1c9c38>;
						fullratiometric-code = <0x4000>;
						read-timeout-uS = <0x7a120>;
						ldo-settling-uS = <0x43>;
						slave-id = <0x00>;
						peripheral-id = <0x90>;
						master-id = <0x00>;
						pmic-device = <0x00>;
						bus-id = <0x00>;
						therm-tbl = <0x0f>;
						phandle = <0x1d>;

						vadc_ch_cfg {

							VPH_PWR {
								hw-channel = <0x8e>;
								settling-delay-uS = <0x00>;
								average-sample = <0x01>;
								decimation-ratio = <0x400>;
								cal-method = "abs ";
								scaling-factor = <0x01 0x03>;
								offset-factor = <0x00>;
								scaling-method = "tomV";
								pull-up-res = <0x00>;
								adc-sid = <0x07>;
								int-table;
							};

							PMIC_TEMP7 {
								hw-channel = <0x03>;
								settling-delay-uS = <0x00>;
								average-sample = <0x01>;
								decimation-ratio = <0x400>;
								cal-method = "abs ";
								scaling-factor = <0x01 0x01>;
								offset-factor = <0xfffbd598>;
								scaling-method = "xtuV";
								pull-up-res = <0x00>;
								adc-sid = <0x07>;
								int-table = "/sw/pmic/adc/therm_table/therm_tb2";
							};

							CHG_TEMP {
								hw-channel = <0x10>;
								settling-delay-uS = <0x00>;
								average-sample = <0x01>;
								decimation-ratio = <0x400>;
								cal-method = "abs ";
								scaling-factor = <0x01 0x01>;
								offset-factor = <0x00>;
								scaling-method = "tomV";
								pull-up-res = <0x00>;
								adc-sid = <0x07>;
								int-table;
							};

							BATT_THERM {
								hw-channel = <0x44>;
								settling-delay-uS = <0x64>;
								average-sample = <0x01>;
								decimation-ratio = <0x400>;
								cal-method = "raio";
								scaling-factor = <0x01 0x01>;
								offset-factor = <0xfffffeef>;
								scaling-method = "xtr ";
								pull-up-res = <0x186a0>;
								adc-sid = <0x07>;
								int-table = "/sw/pmic/adc/therm_table/therm_tb1";
							};

							BATT_THERM_PU_30K {
								hw-channel = <0x24>;
								settling-delay-uS = <0x64>;
								average-sample = <0x01>;
								decimation-ratio = <0x400>;
								cal-method = "raio";
								scaling-factor = <0x01 0x01>;
								offset-factor = <0xfffffeef>;
								scaling-method = "xtr ";
								pull-up-res = <0x7530>;
								adc-sid = <0x07>;
								int-table = "/sw/pmic/adc/therm_table/therm_tb1";
							};

							BATT_THERM_PU_400K {
								hw-channel = <0x64>;
								settling-delay-uS = <0x64>;
								average-sample = <0x01>;
								decimation-ratio = <0x400>;
								cal-method = "raio";
								scaling-factor = <0x01 0x01>;
								offset-factor = <0xfffffeef>;
								scaling-method = "xtr ";
								pull-up-res = <0x61a80>;
								adc-sid = <0x07>;
								int-table = "/sw/pmic/adc/therm_table/therm_tb1";
							};

							BATT_THERM_OHMS {
								hw-channel = <0x44>;
								settling-delay-uS = <0x64>;
								average-sample = <0x01>;
								decimation-ratio = <0x400>;
								cal-method = "raio";
								scaling-factor = <0x01 0x01>;
								offset-factor = <0x00>;
								scaling-method = "res ";
								pull-up-res = <0x186a0>;
								adc-sid = <0x07>;
								int-table;
							};

							BATT_ID_OHMS {
								hw-channel = <0x45>;
								settling-delay-uS = <0x64>;
								average-sample = <0x01>;
								decimation-ratio = <0x400>;
								cal-method = "raio";
								scaling-factor = <0x01 0x01>;
								offset-factor = <0x00>;
								scaling-method = "res ";
								pull-up-res = <0x186a0>;
								adc-sid = <0x07>;
								int-table;
							};

							BATT_ID_OHMS_PU_30K {
								hw-channel = <0x25>;
								settling-delay-uS = <0x64>;
								average-sample = <0x01>;
								decimation-ratio = <0x400>;
								cal-method = "raio";
								scaling-factor = <0x01 0x01>;
								offset-factor = <0x00>;
								scaling-method = "res ";
								pull-up-res = <0x7530>;
								adc-sid = <0x07>;
								int-table;
							};

							BATT_ID_OHMS_PU_400K {
								hw-channel = <0x65>;
								settling-delay-uS = <0x64>;
								average-sample = <0x01>;
								decimation-ratio = <0x400>;
								cal-method = "raio";
								scaling-factor = <0x01 0x01>;
								offset-factor = <0x00>;
								scaling-method = "res ";
								pull-up-res = <0x61a80>;
								adc-sid = <0x07>;
								int-table;
							};

							VBATT {
								hw-channel = <0x8f>;
								settling-delay-uS = <0x00>;
								average-sample = <0x01>;
								decimation-ratio = <0x400>;
								cal-method = "abs ";
								scaling-factor = <0x01 0x03>;
								offset-factor = <0x00>;
								scaling-method = "tomV";
								pull-up-res = <0x00>;
								adc-sid = <0x07>;
								int-table;
							};

							VBATT_2S {
								hw-channel = <0x8f>;
								settling-delay-uS = <0x00>;
								average-sample = <0x01>;
								decimation-ratio = <0x400>;
								cal-method = "abs ";
								scaling-factor = <0x01 0x06>;
								offset-factor = <0x00>;
								scaling-method = "tomV";
								pull-up-res = <0x00>;
								adc-sid = <0x07>;
								int-table;
							};

							VBATT_2S_MID {
								hw-channel = <0x96>;
								settling-delay-uS = <0x00>;
								average-sample = <0x01>;
								decimation-ratio = <0x400>;
								cal-method = "abs ";
								scaling-factor = <0x01 0x03>;
								offset-factor = <0x00>;
								scaling-method = "tomV";
								pull-up-res = <0x00>;
								adc-sid = <0x07>;
								int-table;
							};

							USB_IN {
								hw-channel = <0x11>;
								settling-delay-uS = <0x00>;
								average-sample = <0x01>;
								decimation-ratio = <0x400>;
								cal-method = "abs ";
								scaling-factor = <0x01 0x10>;
								offset-factor = <0x00>;
								scaling-method = "tomV";
								pull-up-res = <0x00>;
								adc-sid = <0x07>;
								int-table;
							};

							VWLS {
								hw-channel = <0x12>;
								settling-delay-uS = <0x00>;
								average-sample = <0x01>;
								decimation-ratio = <0x400>;
								cal-method = "abs ";
								scaling-factor = <0x01 0x10>;
								offset-factor = <0x00>;
								scaling-method = "tomV";
								pull-up-res = <0x00>;
								adc-sid = <0x07>;
								int-table;
							};

							USB_IN_I {
								hw-channel = <0x17>;
								settling-delay-uS = <0x00>;
								average-sample = <0x01>;
								decimation-ratio = <0x400>;
								cal-method = "abs ";
								scaling-factor = <0x08 0x19>;
								offset-factor = <0x00>;
								scaling-method = "tomV";
								pull-up-res = <0x00>;
								adc-sid = <0x07>;
								int-table;
							};

							OEM_VID {
								hw-channel = <0x4b>;
								settling-delay-uS = <0x64>;
								average-sample = <0x01>;
								decimation-ratio = <0x400>;
								cal-method = "raio";
								scaling-factor = <0x01 0x01>;
								offset-factor = <0x00>;
								scaling-method = "res ";
								pull-up-res = <0x186a0>;
								adc-sid = <0x01>;
								int-table;
							};

							PM8550_AMUX_THM4 {
								hw-channel = <0x47>;
								settling-delay-uS = <0x64>;
								average-sample = <0x01>;
								decimation-ratio = <0x400>;
								cal-method = "raio";
								scaling-factor = <0x01 0x01>;
								offset-factor = <0xfffffeef>;
								scaling-method = "xtr ";
								pull-up-res = <0x186a0>;
								adc-sid = <0x01>;
								int-table = "/sw/pmic/adc/therm_table/therm_tb1";
							};

							BATT_THERM_GPIO04 {
								hw-channel = <0x4b>;
								settling-delay-uS = <0x64>;
								average-sample = <0x01>;
								decimation-ratio = <0x400>;
								cal-method = "raio";
								scaling-factor = <0x01 0x01>;
								offset-factor = <0xfffffeef>;
								scaling-method = "xtr ";
								pull-up-res = <0x186a0>;
								adc-sid = <0x01>;
								int-table = "/sw/pmic/adc/therm_table/therm_tb1";
							};
						};

						vadc-avg-ch {
							ch-name = "XO_THERM_GPS";
							low-name = "XO_THERM_GPS_LOW";
							med-name = "XO_THERM_GPS_MED";
							high-name = "XO_THERM_GPS_HIGH";
							med-to-low = <0x1400>;
							low-to-med = <0x3c00>;
							high-to-med = <0x8000>;
							med-to-high = <0xa800>;
						};

						gpio-map {

							aux_pin1 {
								pmic-sid = <0x01>;
								gpio-num = <0x03>;
							};
						};
					};
				};

				therm_table {
					phandle = <0x0f>;

					therm_tb1 {
						arr_id = <0x00>;
						table = <0x40dd78 0xe9 0x2dd9e4 0xee 0x20ca24 0xf3 0x17b588 0xf8 0x1152c4 0xfd 0xcc8a8 0x102 0x985e4 0x107 0x7286c 0x10c 0x56d10 0x111 0x425b8 0x116 0x331f8 0x11b 0x27ac4 0x120 0x1f018 0x125 0x186a0 0x12a 0x13560 0x12f 0xf6e0 0x134 0xc60c 0x139 0x9fc4 0x13e 0x81b0 0x143 0x69dc 0x148 0x56b8 0x14d 0x477c 0x152 0x3b60 0x157 0x3138 0x15c 0x2968 0x161 0x22ba 0x166 0x1d4c 0x16b 0x18d8 0x170 0x1522 0x175 0x120c 0x17a 0xf82 0x17f 0xd5c 0x184 0xb86 0x189 0xa00 0x18e>;
						phandle = <0x1e>;
					};

					therm_tb2 {
						arr_id = <0x01>;
						table = <0x69e24 0x34008 0x7380c 0x38e28 0x7d190 0x3dc48 0x86a4c 0x42a68 0x902a4 0x47888 0x99a34 0x4c6a8 0xa30fc 0x514c8 0xac760 0x562e8 0xb5c98 0x5b108 0xbf0a4 0x5ff28 0xc8384 0x64d48>;
						phandle = <0x1f>;
					};
				};
			};

			arb {
				phandle = <0x20>;

				access {
					none;
					ssc;
					secpro;
					invalid;
					aop;
					adsp = <0x00 0x00 0x82 0x01 0x00 0x07 0x8c 0x01 0x00 0x03 0x8c 0x01>;
					apps = <0x00 0x01 0x8b 0x01 0x00 0x01 0x8e 0x01 0x00 0x07 0x89 0x01 0x00 0x00 0xb8 0x01 0x00 0x03 0x8e 0x01 0x00 0x03 0x8f 0x01>;
					tz;
					mss;
					uefi = <0x00 0x00 0x08 0x01 0x00 0x07 0x08 0x01 0x00 0x00 0x54 0x01>;
					phandle = <0x21>;
				};

				mgpi {
					compatible = "qcom,arb_mgpi";
					phandle = <0x22>;
				};

				pvc {
					compatible = "qcom,arb_pvc";
					phandle = <0x23>;
				};
			};
		};

		smem {
			compatible = "qcom,smem";
			smem-vers = <0xc0000>;
			smem-toc-vers = <0x01>;
			smem-max-items = <0x28e>;

			smem-partitions {

				part-01 {
					size = <0x60000>;
					flags = <0x03>;
					host0 = <0x00>;
					host1 = <0x02>;
					size-cacheline = <0x20>;
					exclusion-sizes = <0x00 0x00 0x00 0x00>;
				};

				part-02 {
					size = <0x20000>;
					flags = <0x03>;
					host0 = <0x00>;
					host1 = <0x05>;
					size-cacheline = <0x20>;
					exclusion-sizes = <0x00 0x00 0x00 0x00>;
				};

				part-03 {
					size = <0x2000>;
					flags = <0x03>;
					host0 = <0x07>;
					host1 = <0x05>;
					size-cacheline = <0x20>;
					exclusion-sizes = <0x00 0x00 0x00 0x00>;
				};

				part-04 {
					size = <0x4000>;
					flags = <0x03>;
					host0 = <0x07>;
					host1 = <0x02>;
					size-cacheline = <0x20>;
					exclusion-sizes = <0x00 0x00 0x00 0x00>;
				};

				part-05 {
					size = <0x2000>;
					flags = <0x03>;
					host0 = <0x07>;
					host1 = <0x01>;
					size-cacheline = <0x20>;
					exclusion-sizes = <0x00 0x00 0x00 0x00>;
				};

				part-06 {
					size = <0x7c000>;
					flags = <0x03>;
					host0 = <0x00>;
					host1 = <0x01>;
					size-cacheline = <0x20>;
					exclusion-sizes = <0x00 0x00 0x00 0x00>;
				};

				part-07 {
					size = <0x30000>;
					flags = <0x03>;
					host0 = <0x01>;
					host1 = <0x02>;
					size-cacheline = <0x20>;
					exclusion-sizes = <0x00 0x00 0x00 0x00>;
				};

				part-08 {
					size = <0x2000>;
					flags = <0x03>;
					host0 = <0x00>;
					host1 = <0x0e>;
					size-cacheline = <0x20>;
					exclusion-sizes = <0x00 0x00 0x00 0x00>;
				};

				part-09 {
					size = <0x2000>;
					flags = <0x03>;
					host0 = <0x01>;
					host1 = <0x0e>;
					size-cacheline = <0x20>;
					exclusion-sizes = <0x00 0x00 0x00 0x00>;
				};

				part-10 {
					size = <0x4000>;
					flags = <0x03>;
					host0 = <0x0d>;
					host1 = <0x07>;
					size-cacheline = <0x20>;
					exclusion-sizes = <0x00 0x00 0x00 0x00>;
				};

				part-11 {
					size = <0x40000>;
					flags = <0x03>;
					host0 = <0x0d>;
					host1 = <0x00>;
					size-cacheline = <0x20>;
					exclusion-sizes = <0x00 0x00 0x00 0x00>;
				};

				part-12 {
					size = <0x20000>;
					flags = <0x03>;
					host0 = <0x0d>;
					host1 = <0x01>;
					size-cacheline = <0x20>;
					exclusion-sizes = <0x00 0x00 0x00 0x00>;
				};

				part-13 {
					size = <0x20000>;
					flags = <0x03>;
					host0 = <0x0d>;
					host1 = <0x02>;
					size-cacheline = <0x20>;
					exclusion-sizes = <0x00 0x00 0x00 0x00>;
				};

				part-14 {
					size = <0x00>;
					flags = <0x00>;
					host0 = <0xffff>;
					host1 = <0xffff>;
					size-cacheline = <0x00>;
					exclusion-sizes = <0x00 0x00 0x00 0x00>;
				};
			};
		};

		seclib {
			compatible = "qcom,seclib";

			lcp_dare {
				smmu_pt = <0x05>;
			};
		};

		oplus_chg {

			chg_1 {
				support_project = <0x5cfb 0x5d39 0x5d3a 0x5c39 0x606f 0x5c46 0x5ca6 0x5e93 0x5e94>;
				support_2s_battery_with_1s_pmic = [01];
				support_get_temp_by_subboard_ntc = [01];
				support_get_temp_by_subboard_ntc_adc_channel = [02];
				apply-float-voltage = [01];
				cold-bat-decidegc = [0a];
				float-voltage-mv = <0x1176>;
				over_high_temp_thr = [3c];
				high-temp-scheme = <0x02>;
			};
		};

		clk_pegging_node {
			cx_corner = <0x100 0x05>;
			ddr_min_max_freq = <0xff 0xff>;
			shub_min_max_freq = <0xff 0xff>;
			test_mode = <0x00>;
		};

		qntm_def {
			compatible = "qcom,qntm_def";

			qntm_dym_sid_info_type_1 {
				subsys = <0x02>;
				share_method = <0x02>;
				avmid = <0x00>;
				subsys_name = "LPASS";
				sid = <0x00>;
				input_base = <0x3000002>;
				csid = <0x03>;
				mask = <0x80>;
			};

			qntm_dym_sid_info_type_2 {
				subsys = <0x04>;
				share_method = <0x02>;
				avmid = <0x00>;
				subsys_name = "COMPUTE";
				sid = <0xc01>;
				input_base = <0x3000001>;
				csid = <0x01>;
				mask = <0x00>;
			};

			qntm_dym_sid_info_type_3 {
				subsys = <0x05>;
				share_method = <0x03>;
				avmid = <0x0f>;
				subsys_name = <0x00>;
				sid = <0x00>;
				input_base = <0x00>;
				csid = <0x00>;
				mask = <0x00>;
			};
		};

		quantum {
			compatible = "qcom,quantum";
			enter_quantum = <0x00>;
		};

		smp2p {
			compatible = "qcom,smp2p";
			fflags = <0x01>;
			max-entries = <0x10>;

			smp2p-interrupts {

				intr-01 {
					dest = <0x02>;
					proc = <0x03>;
					irq = <0x02>;
				};

				intr-02 {
					dest = <0x05>;
					proc = <0x06>;
					irq = <0x02>;
				};

				intr-03 {
					dest = <0x01>;
					proc = <0x02>;
					irq = <0x02>;
				};

				intr-04 {
					dest = <0x0d>;
					proc = <0x18>;
					irq = <0x02>;
				};

				intr-05 {
					dest = <0xffff>;
					proc = <0x88>;
					irq = <0xffffffff>;
				};
			};
		};

		glink {
			compatible = "qcom,glink";

			xport-smem-config {

				edge-01 {
					remote-host = <0x02>;
					fifo-size = <0x4000>;
					mtu-size = <0x1000>;
					irq-out = <0x03 0x00>;
					default-qos = <0x01>;
					custom-fifo-alloc = <0x00>;
					clear-interrupt = <0x00>;
				};

				edge-02 {
					remote-host = <0x05>;
					fifo-size = <0x4000>;
					mtu-size = <0x1000>;
					irq-out = <0x06 0x00>;
					default-qos = <0x01>;
					custom-fifo-alloc = <0x00>;
					clear-interrupt = <0x00>;
				};

				edge-03 {
					remote-host = <0x01>;
					fifo-size = <0x4000>;
					mtu-size = <0x1000>;
					irq-out = <0x02 0x00>;
					default-qos = <0x01>;
					custom-fifo-alloc = <0x00>;
					clear-interrupt = <0x00>;
				};

				edge-04 {
					remote-host = <0x0d>;
					fifo-size = <0x4000>;
					mtu-size = <0x1000>;
					irq-out = <0x18 0x00>;
					default-qos = <0x01>;
					custom-fifo-alloc = <0x00>;
					clear-interrupt = <0x00>;
				};
			};
		};
	};

	__symbols__ {
		soc = "/soc";
		buttons = "/soc/buttons";
		tlmm = "/soc/pinctrl@f100000";
		sdc2_cdc_dtest_out_mirnat_0 = "/soc/pinctrl@f100000/sdc2_cdc_dtest_out_mirnat_0";
		sdc2_cdc_dtest_out_mirnat_1 = "/soc/pinctrl@f100000/sdc2_cdc_dtest_out_mirnat_1";
		sdc2_data0 = "/soc/pinctrl@f100000/sdc2_data0";
		sdc2_data1 = "/soc/pinctrl@f100000/sdc2_data1";
		sdc2_data2 = "/soc/pinctrl@f100000/sdc2_data2";
		sdc2_data3 = "/soc/pinctrl@f100000/sdc2_data3";
		sdc2_fb_clk = "/soc/pinctrl@f100000/sdc2_fb_clk";
		sdc2_cmd = "/soc/pinctrl@f100000/sdc2_cmd";
		sdc2_clk = "/soc/pinctrl@f100000/sdc2_clk";
		sdc2_active = "/soc/pinctrl@f100000/sdc2_active";
		ufs = "/soc/ufs0@1D80000";
		pil_proxy_vote = "/soc/pil/pil_proxy_vote";
		APPS_MMU500_SMMU_APP_handle = "/soc/iort/APPS_MMU500_SMMU_APP";
		GPU_GFX_MMU500_SMMU_GFX_handle = "/soc/iort/GPU_GFX_MMU500_SMMU_GFX";
		sdcc = "/soc/sdc1@8804000";
		smp2p_err_fatal_handle = "/soc/ssr/smp2p_err_fatal";
		smp2p_err_ready_handle = "/soc/ssr/smp2p_err_ready";
		smp2p_proxy_unvote_handle = "/soc/ssr/smp2p_proxy_unvote";
		smp2p_stop_ack_handle = "/soc/ssr/smp2p_stop_ack";
		sw = "/sw";
		pm = "/sw/pmic/pm";
		psi = "/sw/pmic/psi";
		adc = "/sw/pmic/adc";
		vadc = "/sw/pmic/adc/vadc";
		pm8550b = "/sw/pmic/adc/vadc/spmi-vadc";
		therm_table = "/sw/pmic/adc/therm_table";
		sys_therm_tb = "/sw/pmic/adc/therm_table/therm_tb1";
		pmic_die_temp_tb = "/sw/pmic/adc/therm_table/therm_tb2";
		arb = "/sw/pmic/arb";
		access = "/sw/pmic/arb/access";
		mgpi = "/sw/pmic/arb/mgpi";
		pvc = "/sw/pmic/arb/pvc";
	};
};
